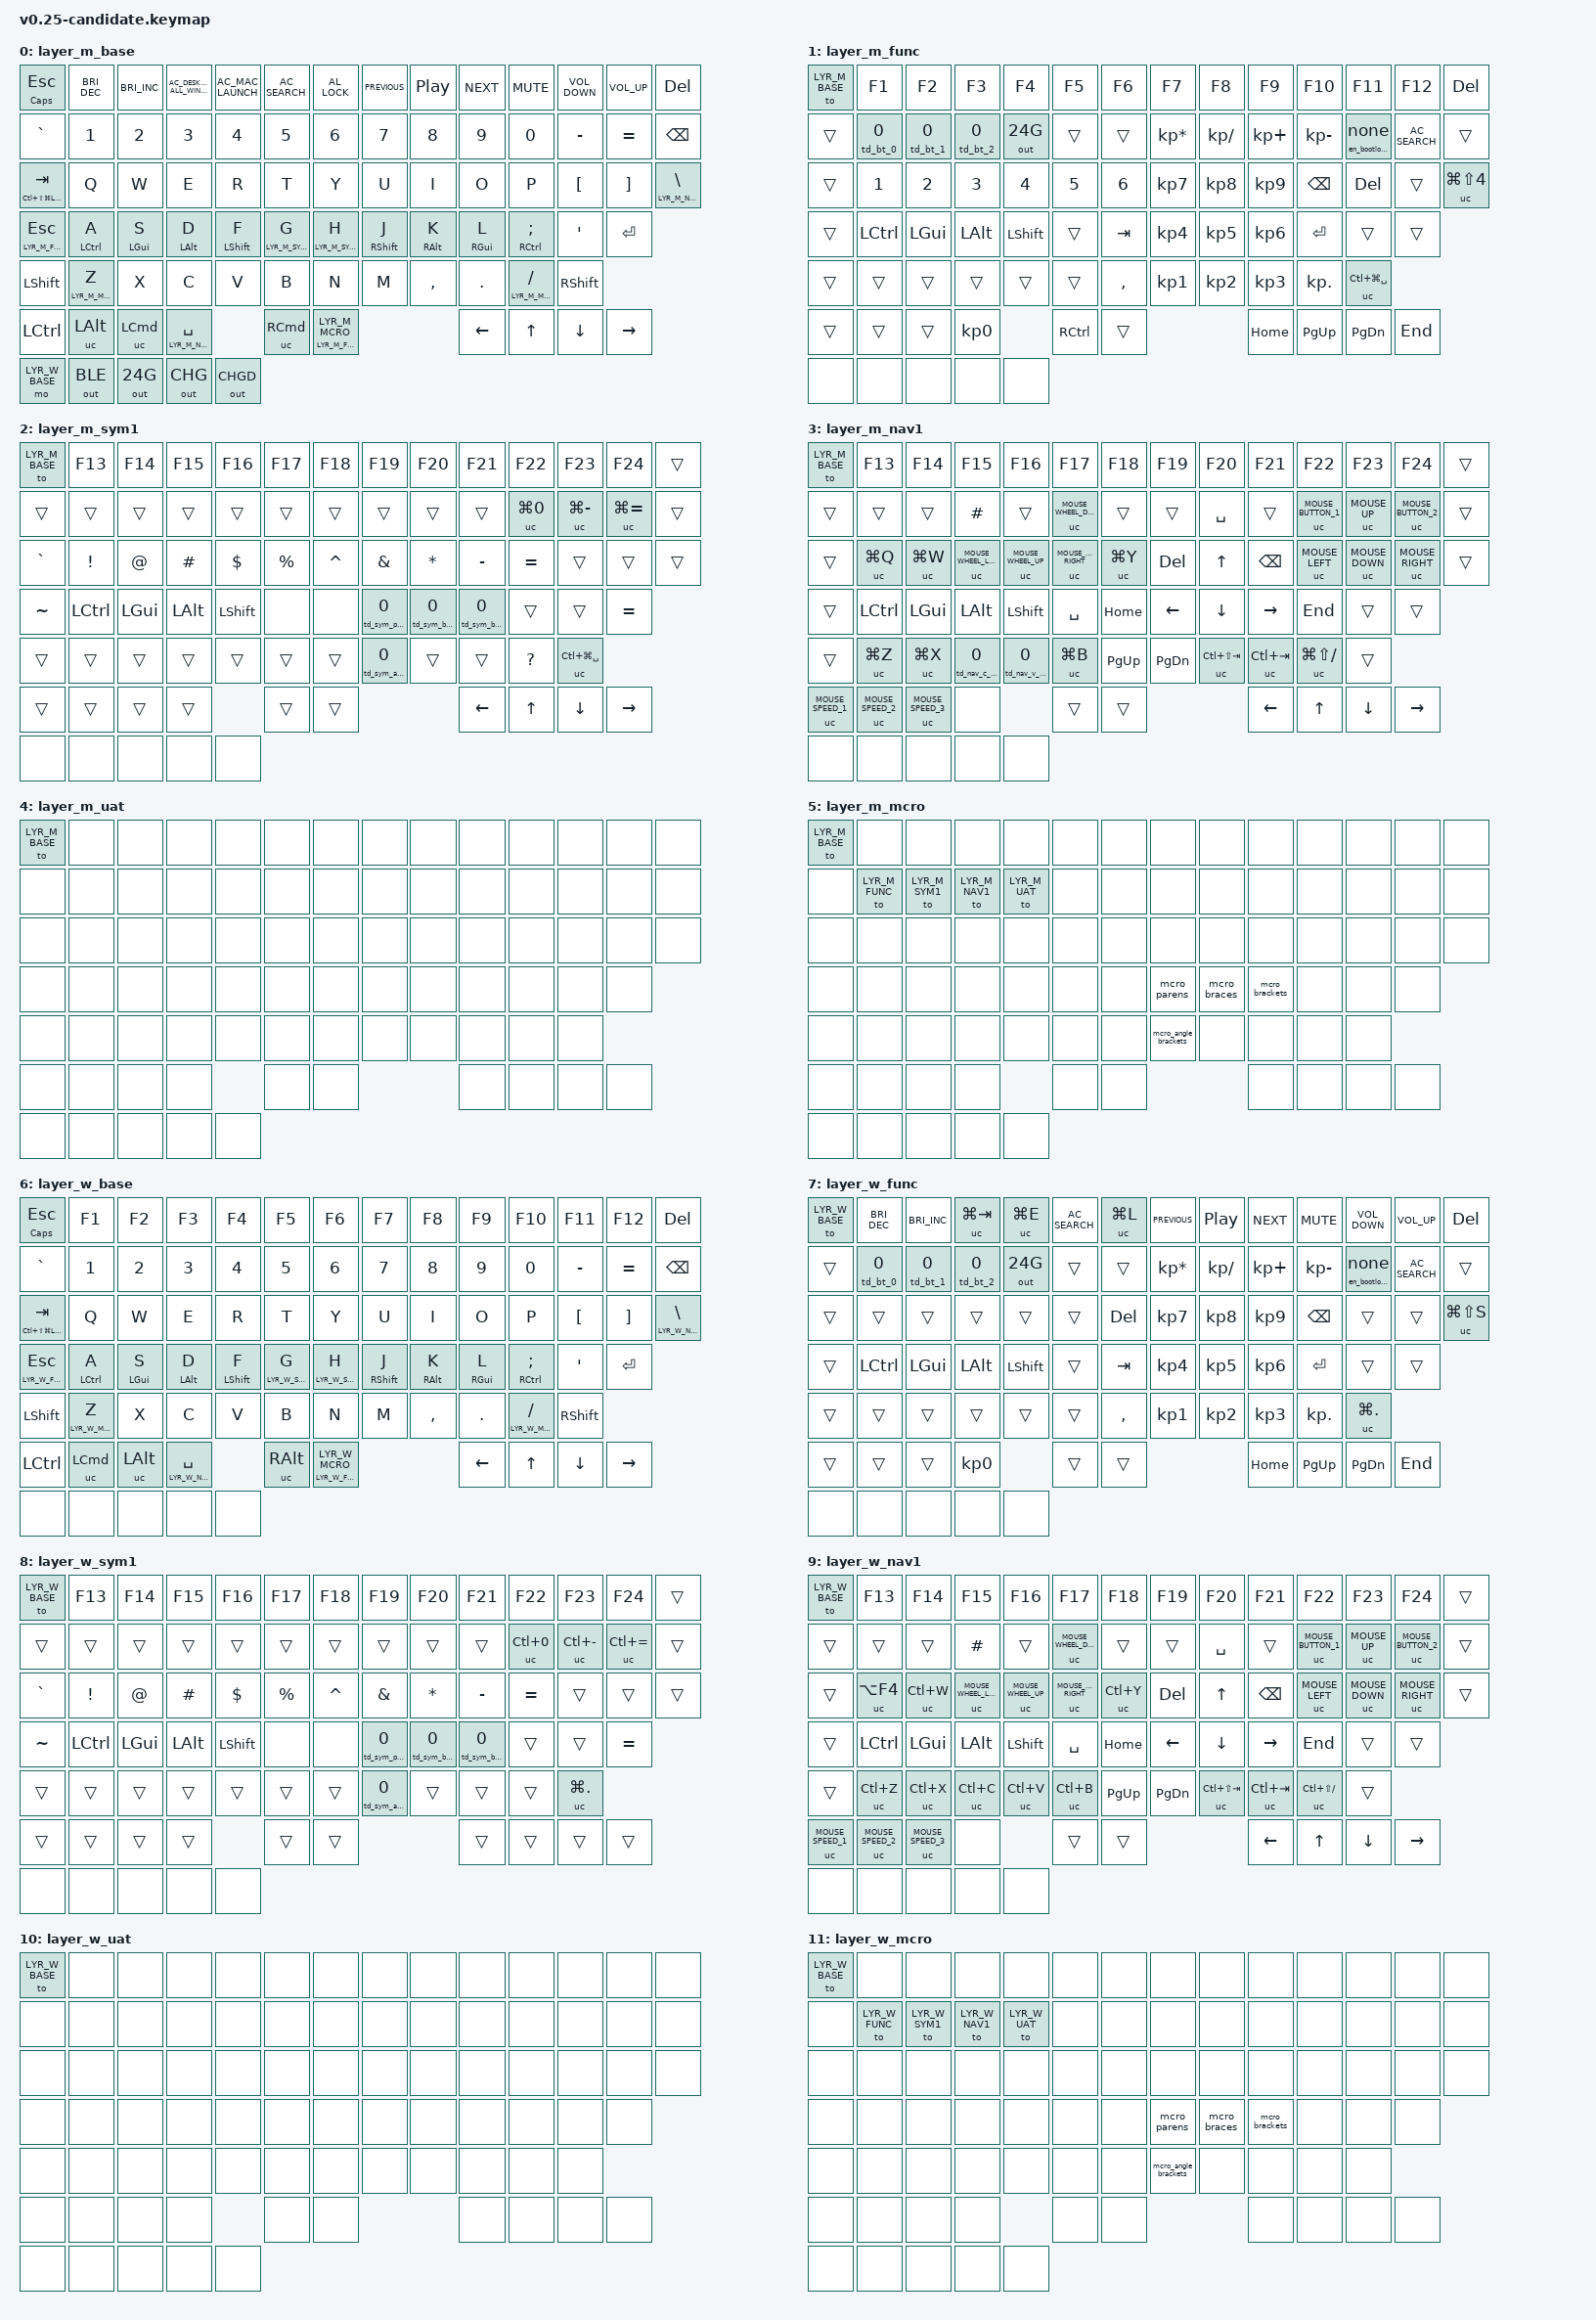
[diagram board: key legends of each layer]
/*
 * Keychron B1 Pro v0.25 candidate.
 * SYMBOL Layers (2 & 8): Reduced bracket tap-dance to 2 taps max (tap: open, double-tap: close) with 350ms threshold.
 *   Restored direct &kp MINUS and &kp EQUAL (Shift + F yields _ and +; rapid double-tap yields -- and ==).
 * MACRO Layers (5 & 11): Momentary layer access via hold Z or hold / (FSLH). Assigned auto-closing bracket macros (open + close + left arrow) to J, K, L, M.
 */

#include <behaviors.dtsi>
#include <dt-bindings/zmk/keys.h>
#include <dt-bindings/zmk/bt.h>
#include <dt-bindings/zmk/outputs.h>

#define LYR_M_BASE        0
#define LYR_M_FUNC        1
#define LYR_M_SYM1        2
#define LYR_M_NAV1        3
#define LYR_M_UAT         4
#define LYR_M_MCRO        5
#define LYR_W_BASE        6
#define LYR_W_FUNC        7
#define LYR_W_SYM1        8
#define LYR_W_NAV1        9
#define LYR_W_UAT         10
#define LYR_W_MCRO        11

#define MOUSE_UP          0x00CD
#define MOUSE_DOWN        0x00CE
#define MOUSE_LEFT        0x00CF
#define MOUSE_RIGHT       0x00D0
#define MOUSE_BUTTON_1    0x00D1
#define MOUSE_BUTTON_2    0x00D2
#define MOUSE_WHEEL_UP    0x00D9
#define MOUSE_WHEEL_DOWN  0x00DA
#define MOUSE_WHEEL_LEFT  0x00DB
#define MOUSE_WHEEL_RIGHT 0x00DC
#define MOUSE_SPEED_1     0x00DD
#define MOUSE_SPEED_2     0x00DE
#define MOUSE_SPEED_3     0x00DF

/ {
    ZMK_MACRO(en_bootloader, bindings = <&bootloader>;)
    ZMK_MACRO(mcro_parens, bindings = <&kp LPAR &kp RPAR &kp LEFT>;)
    ZMK_MACRO(mcro_braces, bindings = <&kp LBRC &kp RBRC &kp LEFT>;)
    ZMK_MACRO(mcro_brackets, bindings = <&kp LBKT &kp RBKT &kp LEFT>;)
    ZMK_MACRO(mcro_angle_brackets, bindings = <&kp LT &kp GT &kp LEFT>;)

    long_press_bootloader: long_press_bootloader {
        compatible = "zmk,behavior-hold-tap";
        label = "LP_BOOTLOADER";
        #binding-cells = <2>;
        flavor = "tap-preferred";
        tapping-term-ms = <3000>;  // delay amount in ms
        bindings = <&en_bootloader>, <&none>;
    };

    esc_caps: escape_caps_lock {
        compatible = "zmk,behavior-hold-tap";
        label = "ESC_CAPS_LOCK";
        #binding-cells = <2>;
        flavor = "tap-preferred";
        tapping-term-ms = <600>;
        // Use an ordinary press/release for the hold. &kt keeps CLCK down
        // across physical releases, which requires a second hold to finish.
        bindings = <&kp>, <&kp>;
    };

    fn_layer_access: fn_layer_access {
        compatible = "zmk,behavior-hold-tap";
        label = "FN_LAYER_ACCESS";
        #binding-cells = <2>;
        flavor = "tap-preferred";
        tapping-term-ms = <200>;
        bindings = <&mo>, <&sl>;
    };

    td_bt_0: td_bt_0 {
        compatible = "zmk,behavior-tap-dance";
        label = "TD_BT_0";
        #binding-cells = <1>;
        tapping-term-ms = <350>;
        bindings = <&bt BT_SEL 0>, <&bt BT_PAIR 0>;
    };

    td_bt_1: td_bt_1 {
        compatible = "zmk,behavior-tap-dance";
        label = "TD_BT_1";
        #binding-cells = <1>;
        tapping-term-ms = <350>;
        bindings = <&bt BT_SEL 1>, <&bt BT_PAIR 1>;
    };

    td_bt_2: td_bt_2 {
        compatible = "zmk,behavior-tap-dance";
        label = "TD_BT_2";
        #binding-cells = <1>;
        tapping-term-ms = <350>;
        bindings = <&bt BT_SEL 2>, <&bt BT_PAIR 2>;
    };

    td_sym_parens: td_sym_parens {
        compatible = "zmk,behavior-tap-dance";
        label = "TD_SYM_PARENS";
        #binding-cells = <1>;
        tapping-term-ms = <350>;
        bindings = <&kp LPAR>, <&kp RPAR>;
    };

    td_sym_braces: td_sym_braces {
        compatible = "zmk,behavior-tap-dance";
        label = "TD_SYM_BRACES";
        #binding-cells = <1>;
        tapping-term-ms = <350>;
        bindings = <&kp LBRC>, <&kp RBRC>;
    };

    td_sym_brackets: td_sym_brackets {
        compatible = "zmk,behavior-tap-dance";
        label = "TD_SYM_BRACKETS";
        #binding-cells = <1>;
        tapping-term-ms = <350>;
        bindings = <&kp LBKT>, <&kp RBKT>;
    };

    td_sym_angle_brackets: td_sym_angle_brackets {
        compatible = "zmk,behavior-tap-dance";
        label = "TD_SYM_ANGLE_BRACKETS";
        #binding-cells = <1>;
        tapping-term-ms = <350>;
        bindings = <&kp LT>, <&kp GT>;
    };

    td_nav_c_mac: td_nav_c_mac {
        compatible = "zmk,behavior-tap-dance";
        label = "TD_NAV_C_MAC";
        #binding-cells = <1>;
        tapping-term-ms = <200>;
        bindings = <&uc LG(C)>, <&uc LG(LS(C))>, <&uc LC(LS(C))>;
    };

    td_nav_v_mac: td_nav_v_mac {
        compatible = "zmk,behavior-tap-dance";
        label = "TD_NAV_V_MAC";
        #binding-cells = <1>;
        tapping-term-ms = <200>;
        bindings = <&uc LG(V)>, <&uc LC(V)>, <&uc LC(LS(V))>;
    };

    lhm: left_homerow_mods {
        compatible = "zmk,behavior-hold-tap";
        label = "LEFT_HOMEROW_MODS";
        #binding-cells = <2>;
        flavor = "tap-preferred";
        tapping-term-ms = <200>;
        quick-tap-ms = <175>;
        require-prior-idle-ms = <150>;
        hold-trigger-on-release;
        hold-trigger-key-positions = <
            7 8 9 10 11 12
            20 21 22 23 24 25 26
            34 35 36 37 38 39 40
            47 48 49 50 51 52 53
            60 61 62 63 64 65
            70 71 72 73 74 75
        >;
        bindings = <&kp>, <&kp>;
    };

    rhm: right_homerow_mods {
        compatible = "zmk,behavior-hold-tap";
        label = "RIGHT_HOMEROW_MODS";
        #binding-cells = <2>;
        flavor = "tap-preferred";
        tapping-term-ms = <200>;
        quick-tap-ms = <175>;
        require-prior-idle-ms = <150>;
        hold-trigger-on-release;
        hold-trigger-key-positions = <
            0 1 2 3 4 5 6
            13 14 15 16 17 18 19
            27 28 29 30 31 32 33
            41 42 43 44 45 46
            54 55 56 57 58 59
            66 67 68 69
        >;
        bindings = <&kp>, <&kp>;
    };


    uc: user_custom {
        compatible = "zmk,behavior-key-press";
        label = "USER_CUSTOM";
        #binding-cells = <1>;
    };

    keymap {

    /*
                              ..'
                      ,xNMM.
                    .OMMMMo
                    lMM"
          .;loddo:.  .olloddol;.
        cKMMMMMMMMMMNWMMMMMMMMMM0:
      .KMMMMMMMMMMMMMMMMMMMMMMMWd.
      XMMMMMMMMMMMMMMMMMMMMMMMX.
      ;MMMMMMMMMMMMMMMMMMMMMMMM:
      :MMMMMMMMMMMMMMMMMMMMMMMM:
      .MMMMMMMMMMMMMMMMMMMMMMMMX.
      kMMMMMMMMMMMMMMMMMMMMMMMMWd.
      'XMMMMMMMMMMMMMMMMMMMMMMMMMMk
        'XMMMMMMMMMMMMMMMMMMMMMMMMK.
          kMMMMMMMMMMMMMMMMMMMMMMd
          ;KMMMMMMMWXXWMMMMMMMk.
            "cooc*"    "*coo'"
                                      */
    compatible = "zmk,keymap";
    /* LAYER 0: LYR_M_BASE
    ┏━━━━━━━━━━━┳━━━━━━━━━┳━━━━━━━━━┳━━━━━━━━━┳━━━━━━━━━┳━━━━━━━━━┳━━━━━━━━━┳━━━━━━━━━┳━━━━━━━━━┳━━━━━━━━━┳━━━━━━━━━┳━━━━━━━━━┳━━━━━━━━━┳━━━━━━━━┓
    ┃           ┃         ┃         ┃ MISSION ┃   MAC   ┃  SEARCH ┃ CTRL+ALT┃ PREVIOUS┃ PLAY/   ┃   NEXT  ┃   Vol   ┃         ┃         ┃        ┃
    ┃TAP: ESC   ┃ Bright- ┃ Bright+ ┃ CONTROL ┃ LAUNCH  ┃         ┃    + M  ┃  TRACK  ┃  PAUSE  ┃  TRACK  ┃   Mute  ┃   Vol-  ┃  Vol+   ┃   DEL  ┃
    ┃HOLD: CAPS ┃         ┃         ┃         ┃         ┃         ┃         ┃         ┃         ┃         ┃         ┃         ┃         ┃        ┃
    ┣━━━━━━━┳━━━┻━━━━━┳━━━┻━━━━━┳━━━┻━━━━━┳━━━┻━━━━━┳━━━┻━━━━━┳━━━┻━━━━━┳━━━┻━━━━━┳━━━┻━━━━━┳━━━┻━━━━━┳━━━┻━━━━━┳━━━┻━━━━━┳━━━┻━━━━━┳━━━┻━━━━━━━━┫
    ┃   ~   ┃    !    ┃    @    ┃    #    ┃    $    ┃    %    ┃    ^    ┃    *    ┃    -    ┃    (    ┃    )    ┃    _    ┃    +    ┃            ┃
    ┃   `   ┃    1    ┃    2    ┃    3    ┃    4    ┃    5    ┃    6    ┃    7    ┃    8    ┃    9    ┃    0    ┃    -    ┃    =    ┃    BKSP    ┃
    ┃       ┃         ┃         ┃         ┃         ┃         ┃         ┃         ┃         ┃         ┃         ┃         ┃         ┃            ┃
    ┣━━━━━━━┻━━┳━━━━━━┻━━┳━━━━━━┻━━┳━━━━━━┻━━┳━━━━━━┻━━┳━━━━━━┻━━┳━━━━━━┻━━┳━━━━━━┻━━┳━━━━━━┻━━┳━━━━━━┻━━┳━━━━━━┻━━┳━━━━━━┻━━┳━━━━━━┻━━┳━━━━━━━━━┫
    ┃TAP: TAB  ┃         ┃         ┃         ┃         ┃         ┃         ┃         ┃         ┃         ┃         ┃    {    ┃    }    ┃    |    ┃
    ┃HOLD: HYPR┃    Q    ┃    W    ┃    E    ┃    R    ┃    T    ┃    Y    ┃    U    ┃    I    ┃    O    ┃    P    ┃    [    ┃    ]    ┃    \    ┃
    ┃          ┃         ┃         ┃         ┃         ┃         ┃         ┃         ┃         ┃         ┃         ┃         ┃         ┃         ┃
    ┣━━━━━━━━━━┻┳━━━━━━━━┻┳━━━━━━━━┻┳━━━━━━━━┻┳━━━━━━━━┻┳━━━━━━━━┻┳━━━━━━━━┻┳━━━━━━━━┻┳━━━━━━━━┻┳━━━━━━━━┻┳━━━━━━━━┻┳━━━━━━━━┻┳━━━━━━━━┻━━━━━━━━━┫
    ┃TAP=ESC    ┃ TAP=A   ┃ TAP=S   ┃ TAP=D   ┃ TAP=F   ┃ TAP=G   ┃ TAP=H   ┃ TAP=J   ┃ TAP=K   ┃ TAP=L   ┃ TAP=;/: ┃    "    ┃                  ┃
    ┃HOLD:MO(1) ┃ HLD=    ┃ HLD=    ┃ HLD=    ┃ HLD=    ┃ HLD=    ┃ HLD=    ┃ HLD=    ┃ HLD=    ┃ HLD=    ┃ HLD=    ┃    '    ┃      RETURN      ┃
    ┃           ┃  L_CTRL ┃  L_GUI  ┃  L_ALT  ┃ L_SHIFT ┃   MO(2) ┃   MO(2) ┃ R_SHIFT ┃  R_ALT  ┃  R_GUI  ┃  R_CTRL ┃         ┃                  ┃
    ┣━━━━━━━━━━━┻━━┳━━━━━━┻━━┳━━━━━━┻━━┳━━━━━━┻━━┳━━━━━━┻━━┳━━━━━━┻━━┳━━━━━━┻━━┳━━━━━━┻━━┳━━━━━━┻━━┳━━━━━━┻━━┳━━━━━━┻━━┳━━━━━━┻━━━━━━━━━━━━━━━━━━┫
    ┃              ┃         ┃         ┃         ┃         ┃         ┃         ┃         ┃    <    ┃    >    ┃    ?    ┃                         ┃
    ┃   L_SHIFT    ┃    Z    ┃    X    ┃    C    ┃    V    ┃    B    ┃   N     ┃    M    ┃    ,    ┃    .    ┃    /    ┃        R_SHIFT          ┃
    ┃              ┃         ┃         ┃         ┃         ┃         ┃         ┃         ┃         ┃         ┃         ┃                         ┃
    ┣━━━━━━━━━━━┳━━┻━━━━━━━┳━┻━━━━━━━━━╋━━━━━━━━━┻━━━━━━━━━┻━━━━━━━━━┻━━━━━━━━━┻━━━━━━━━━╋━━━━━━━━━┻━━━━┳━━━━┻━━━━━┳━┳━┻━━━━━━┳━━━━━━━━━┳━━━━━━━━┫
    ┃           ┃          ┃           ┃                                                 ┃              ┃TAP:OSL(5)┃ ┃        ┃    ↑    ┃        ┃
    ┃  L_CTRL   ┃  L_ALT   ┃   L_CMD   ┃             * &lt LYR_M_NAV1 SPACE *            ┃    R_CMD     ┃HOLD:MO(1)┃ ┃    ←   ┣━━━━━━━━━┫   →    ┃
    ┃           ┃          ┃           ┃                                                 ┃              ┃          ┃ ┃        ┃    ↓    ┃        ┃
    ┗━━━━━━━━━━━┻━━━━━━━━━━┻━━━━━━━━━━━┻━━━━━━━━━━━━━━━━━━━━━━━━━━━━━━━━━━━━━━━━━━━━━━━━━┻━━━━━━━━━━━━━━┻━━━━━━━━━━┛ ┗━━━━━━━━┻━━━━━━━━━┻━━━━━━━━┛
    */

    layer_m_base {
      bindings = <
        //ESC                     //f1                   //f2                  //f3                               //f4                 //f5              //f6              //f7            //f8              //f9        //f10            //f11              //f12            //DEL
        &esc_caps CLCK ESC        &kp C_BRIGHTNESS_DEC   &kp C_BRIGHTNESS_INC  &kp C_AC_DESKTOP_SHOW_ALL_WINDOWS  &kp C_AC_MAC_LAUNCH  &kp C_AC_SEARCH   &kp C_AL_LOCK     &kp C_PREVIOUS  &kp C_PLAY_PAUSE  &kp C_NEXT  &kp C_MUTE       &kp C_VOLUME_DOWN  &kp C_VOLUME_UP  &kp DEL
        &kp GRAVE                 &kp N1                 &kp N2                &kp N3                             &kp N4               &kp N5            &kp N6            &kp N7          &kp N8            &kp N9      &kp N0           &kp MINUS          &kp EQUAL        &kp BSPC
        &mt LC(LS(LG(LALT))) TAB  &kp Q                  &kp W                 &kp E                              &kp R                &kp T             &kp Y             &kp U           &kp I             &kp O       &kp P            &kp LBKT           &kp RBKT         &lt LYR_M_NAV1 BSLH
        &lt LYR_M_FUNC ESC        &lhm LCTRL A           &lhm LGUI S           &lhm LALT D                        &lhm LSHFT F         &lt LYR_M_SYM1 G  &lt LYR_M_SYM1 H  &rhm RSHFT J    &rhm RALT K       &rhm RGUI L &rhm RCTRL SEMI  &kp SQT            &kp RET
        &kp LSHFT                 &lt LYR_M_MCRO Z       &kp X                 &kp C                              &kp V                &kp B             &kp N             &kp M           &kp COMMA         &kp DOT     &lt LYR_M_MCRO FSLH  &kp RSHFT
        &kp LCTRL                 &uc LALT               &uc LCMD              &lt LYR_M_NAV1 SPACE                                    &uc RCMD          &fn_layer_access LYR_M_FUNC LYR_M_MCRO              &kp LEFT    &kp UP           &kp DOWN           &kp RIGHT
        &mo LYR_W_BASE            &out OUT_BLE           &out OUT_24G          &out OUT_CHG                       &out OUT_CHGD
      >;
    };

    /* LAYER 1: LYR_M_FUNC
    ┏━━━━━━━━━━━┳━━━━━━━━━┳━━━━━━━━━┳━━━━━━━━━┳━━━━━━━━━┳━━━━━━━━━┳━━━━━━━━━┳━━━━━━━━━┳━━━━━━━━━┳━━━━━━━━━┳━━━━━━━━━┳━━━━━━━━━┳━━━━━━━━━┳━━━━━━━━┓
    ┃           ┃         ┃         ┃         ┃         ┃         ┃         ┃         ┃         ┃         ┃         ┃         ┃         ┃        ┃
    ┃TO(LYR_M_  ┃   F1    ┃   F2    ┃   F3    ┃   F4    ┃   F5    ┃   F6    ┃    F7   ┃    F8   ┃    F9   ┃   F10   ┃   F11   ┃   F12   ┃  DEL   ┃
    ┃   BASE)   ┃         ┃         ┃         ┃         ┃         ┃         ┃         ┃         ┃         ┃         ┃         ┃         ┃        ┃
    ┣━━━━━━━┳━━━┻━━━━━┳━━━┻━━━━━┳━━━┻━━━━━┳━━━┻━━━━━┳━━━┻━━━━━┳━━━┻━━━━━┳━━━┻━━━━━┳━━━┻━━━━━┳━━━┻━━━━━┳━━━┻━━━━━┳━━━┻━━━━━┳━━━┻━━━━━┳━━━┻━━━━━━━━┫
    ┃       ┃TAP:BT1  ┃TAP:BT2  ┃TAP:BT3  ┃  2.4G   ┃         ┃         ┃ NUMPAD  ┃ NUMPAD  ┃ NUMPAD  ┃ NUMPAD  ┃         ┃         ┃            ┃
    ┃   ▼   ┃DBL:PAIR1┃DBL:PAIR2┃DBL:PAIR3┃  PAIR   ┃    ▼    ┃    ▼    ┃    ×    ┃    ÷    ┃    +    ┃    −    ┃   Boot  ┃  Search ┃     ▼      ┃
    ┃       ┃         ┃         ┃         ┃         ┃         ┃         ┃         ┃         ┃         ┃         ┃         ┃         ┃            ┃
    ┣━━━━━━━┻━━┳━━━━━━┻━━┳━━━━━━┻━━┳━━━━━━┻━━┳━━━━━━┻━━┳━━━━━━┻━━┳━━━━━━┻━━┳━━━━━━┻━━┳━━━━━━┻━━┳━━━━━━┻━━┳━━━━━━┻━━┳━━━━━━┻━━┳━━━━━━┻━━┳━━━━━━━━━┫
    ┃          ┃    !    ┃    @    ┃    #    ┃    $    ┃    %    ┃    ^    ┃ NUMPAD  ┃ NUMPAD  ┃ NUMPAD  ┃         ┃         ┃         ┃ Screen  ┃
    ┃     ▼    ┃    1    ┃    2    ┃    3    ┃    4    ┃    5    ┃    6    ┃    7    ┃    8    ┃    9    ┃BACKSPACE┃  DELETE ┃    ▼    ┃ Cap-Mac ┃
    ┃          ┃         ┃         ┃         ┃         ┃         ┃         ┃         ┃         ┃         ┃         ┃         ┃         ┃         ┃
    ┣━━━━━━━━━━┻┳━━━━━━━━┻┳━━━━━━━━┻┳━━━━━━━━┻┳━━━━━━━━┻┳━━━━━━━━┻┳━━━━━━━━┻┳━━━━━━━━┻┳━━━━━━━━┻┳━━━━━━━━┻┳━━━━━━━━┻┳━━━━━━━━┻┳━━━━━━━━┻━━━━━━━━━┫
    ┃           ┃         ┃         ┃         ┃         ┃         ┃ NUMPAD  ┃ NUMPAD  ┃ NUMPAD  ┃ NUMPAD  ┃         ┃         ┃                  ┃
    ┃   __▼__   ┃  L_CTRL ┃  L_GUI  ┃  L_ALT  ┃ L_SHIFT ┃     ▼   ┃   TAB   ┃    4    ┃    5    ┃    6    ┃  ENTER  ┃     ▼   ┃         ▼        ┃
    ┃           ┃         ┃         ┃         ┃         ┃         ┃         ┃         ┃         ┃         ┃         ┃         ┃                  ┃
    ┣━━━━━━━━━━━┻━━┳━━━━━━┻━━┳━━━━━━┻━━┳━━━━━━┻━━┳━━━━━━┻━━┳━━━━━━┻━━┳━━━━━━┻━━┳━━━━━━┻━━┳━━━━━━┻━━┳━━━━━━┻━━┳━━━━━━┻━━┳━━━━━━┻━━━━━━━━━━━━━━━━━━┫
    ┃              ┃         ┃         ┃         ┃         ┃         ┃         ┃ NUMPAD  ┃ NUMPAD  ┃ NUMPAD  ┃ NUMPAD  ┃                         ┃
    ┃       ▼      ┃     ▼   ┃     ▼   ┃     ▼   ┃    ▼    ┃    ▼    ┃    ,    ┃    1    ┃    2    ┃    3    ┃    .    ┃        Emoji-m          ┃
    ┃              ┃         ┃         ┃         ┃         ┃         ┃         ┃         ┃         ┃         ┃         ┃                         ┃
    ┣━━━━━━━━━━━┳━━┻━━━━━━━┳━┻━━━━━━━━━╋━━━━━━━━━┻━━━━━━━━━┻━━━━━━━━━┻━━━━━━━━━┻━━━━━━━━━╋━━━━━━━━━┻━━━━┳━━━━┻━━━━━┳━┳━┻━━━━━━┳━━━━━━━━━┳━━━━━━━━┫
    ┃           ┃          ┃           ┃                     NUMPAD                      ┃              ┃          ┃ ┃        ┃  PgUp   ┃        ┃
    ┃     ▼     ┃     ▼    ┃     ▼     ┃                        0                        ┃    R_CTRL    ┃     ▼    ┃ ┃  Home  ┣━━━━━━━━━┫   End  ┃
    ┃           ┃          ┃           ┃                                                 ┃              ┃          ┃ ┃        ┃  PgDn   ┃        ┃
    ┗━━━━━━━━━━━┻━━━━━━━━━━┻━━━━━━━━━━━┻━━━━━━━━━━━━━━━━━━━━━━━━━━━━━━━━━━━━━━━━━━━━━━━━━┻━━━━━━━━━━━━━━┻━━━━━━━━━━┛ ┗━━━━━━━━┻━━━━━━━━━┻━━━━━━━━┛
    */
    layer_m_func {
      bindings = <
        //ESC           //F1        //F2        //F3        //f4          //f5    //f6       //f7             //f8           //f9         //f10         //f11                       //f12             //DEL
        &to LYR_M_BASE  &kp F1      &kp F2      &kp F3      &kp F4        &kp F5  &kp F6     &kp F7           &kp F8         &kp F9       &kp F10       &kp F11                     &kp F12           &kp DEL
        &trans          &td_bt_0 0  &td_bt_1 0  &td_bt_2 0  &out OUT_24G  &trans  &trans     &kp KP_MULTIPLY  &kp KP_DIVIDE  &kp KP_PLUS  &kp KP_MINUS  &long_press_bootloader 0 0  &kp C_AC_SEARCH   &trans
        &trans          &kp N1      &kp N2      &kp N3      &kp N4        &kp N5  &kp N6     &kp KP_N7        &kp KP_N8      &kp KP_N9    &kp BSPC      &kp DEL                      &trans            &uc LG(LS(N4))
        &trans          &kp LCTRL   &kp LGUI    &kp LALT    &kp LSHFT     &trans  &kp TAB    &kp KP_N4        &kp KP_N5      &kp KP_N6    &kp RET       &trans                                        &trans
        &trans          &trans      &trans      &trans      &trans        &trans  &kp COMMA  &kp KP_N1        &kp KP_N2      &kp KP_N3    &kp KP_DOT    &uc LC(LG(SPACE))
        &trans          &trans      &trans      &kp KP_N0   &kp RCTRL     &trans  &kp HOME   &kp PG_UP        &kp PG_DN      &kp END
        &none           &none       &none       &none       &none
      >;
    };

    /* LAYER 2: LYR_M_SYM1
    ┏━━━━━━━━━━━┳━━━━━━━━━┳━━━━━━━━━┳━━━━━━━━━┳━━━━━━━━━┳━━━━━━━━━┳━━━━━━━━━┳━━━━━━━━━┳━━━━━━━━━┳━━━━━━━━━┳━━━━━━━━━┳━━━━━━━━━┳━━━━━━━━━┳━━━━━━━━┓
    ┃           ┃         ┃         ┃         ┃         ┃         ┃         ┃         ┃         ┃         ┃         ┃         ┃         ┃        ┃
    ┃TO(LYR_M_  ┃   F13   ┃   F14   ┃   F15   ┃   F16   ┃   F17   ┃   F18   ┃   F19   ┃   F20   ┃   F21   ┃   F22   ┃   F23   ┃   F24   ┃   ▼    ┃
    ┃   BASE)   ┃         ┃         ┃         ┃         ┃         ┃         ┃         ┃         ┃         ┃         ┃         ┃         ┃        ┃
    ┣━━━━━━━┳━━━┻━━━━━┳━━━┻━━━━━┳━━━┻━━━━━┳━━━┻━━━━━┳━━━┻━━━━━┳━━━┻━━━━━┳━━━┻━━━━━┳━━━┻━━━━━┳━━━┻━━━━━┳━━━┻━━━━━┳━━━┻━━━━━┳━━━┻━━━━━┳━━━┻━━━━━━━━┫
    ┃       ┃         ┃         ┃         ┃         ┃         ┃         ┃         ┃         ┃         ┃         ┃         ┃         ┃            ┃
    ┃   ▼   ┃    ▼    ┃    ▼    ┃    ▼    ┃    ▼    ┃    ▼    ┃    ▼    ┃    ▼    ┃    ▼    ┃    ▼    ┃ LG(N0)  ┃LG(MINUS)┃LG(EQUAL)┃     ▼      ┃
    ┃       ┃         ┃         ┃         ┃         ┃         ┃         ┃         ┃         ┃         ┃         ┃         ┃         ┃            ┃
    ┣━━━━━━━┻━━┳━━━━━━┻━━┳━━━━━━┻━━┳━━━━━━┻━━┳━━━━━━┻━━┳━━━━━━┻━━┳━━━━━━┻━━┳━━━━━━┻━━┳━━━━━━┻━━┳━━━━━━┻━━┳━━━━━━┻━━┳━━━━━━┻━━┳━━━━━━┻━━┳━━━━━━━━━┫
    ┃          ┃         ┃         ┃         ┃         ┃         ┃         ┃         ┃         ┃         ┃         ┃         ┃         ┃S(KC_    ┃
    ┃    [`]   ┃   [!]   ┃   [@]   ┃   [#]   ┃   [$]   ┃   [%]   ┃   [^]   ┃   [&]   ┃   [*]   ┃   [-]   ┃   [=]   ┃    ▼    ┃    ▼    ┃  BSLS)  ┃
    ┃          ┃         ┃         ┃         ┃         ┃         ┃         ┃         ┃         ┃         ┃         ┃         ┃         ┃         ┃
    ┣━━━━━━━━━━┻┳━━━━━━━━┻┳━━━━━━━━┻┳━━━━━━━━┻┳━━━━━━━━┻┳━━━━━━━━┻┳━━━━━━━━┻┳━━━━━━━━┻┳━━━━━━━━┻┳━━━━━━━━┻┳━━━━━━━━┻┳━━━━━━━━┻┳━━━━━━━━┻━━━━━━━━━┫
    ┃           ┃         ┃         ┃         ┃         ┃    *    ┃   *     ┃ 1TAP: ( ┃ 1TAP: { ┃ 1TAP: [ ┃         ┃         ┃                  ┃
    ┃    [~]    ┃  L_CTRL ┃  L_GUI  ┃  L_ALT  ┃ L_SHIFT ┃  SYMBOL ┃ SYMBOL  ┃ 2TAP: ) ┃ 2TAP: } ┃ 2TAP: ] ┃    ▼    ┃    ▼    ┃       [=]        ┃
    ┃           ┃         ┃         ┃         ┃         ┃    *    ┃   *     ┃         ┃         ┃         ┃         ┃         ┃                  ┃
    ┣━━━━━━━━━━━┻━━┳━━━━━━┻━━┳━━━━━━┻━━┳━━━━━━┻━━┳━━━━━━┻━━┳━━━━━━┻━━┳━━━━━━┻━━┳━━━━━━┻━━┳━━━━━━┻━━┳━━━━━━┻━━┳━━━━━━┻━━┳━━━━━━┻━━━━━━━━━━━━━━━━━━┫
    ┃              ┃         ┃         ┃         ┃         ┃         ┃         ┃ 1TAP: < ┃         ┃         ┃         ┃                         ┃
    ┃       ▼      ┃    ▼    ┃    ▼    ┃    ▼    ┃    ▼    ┃    ▼    ┃    ▼    ┃ 2TAP: > ┃    ▼    ┃    ▼    ┃    ▼    ┃         Emoji-w         ┃
    ┃              ┃         ┃         ┃         ┃         ┃         ┃         ┃         ┃         ┃         ┃         ┃                         ┃
    ┣━━━━━━━━━━━┳━━┻━━━━━━━┳━┻━━━━━━━━━╋━━━━━━━━━┻━━━━━━━━━┻━━━━━━━━━┻━━━━━━━━━┻━━━━━━━━━╋━━━━━━━━━┻━━━━┳━━━━┻━━━━━┳━┳━┻━━━━━━┳━━━━━━━━━┳━━━━━━━━┫
    ┃           ┃          ┃           ┃                                                 ┃              ┃          ┃ ┃        ┃    ↑    ┃        ┃
    ┃     ▼     ┃    ▼     ┃     ▼     ┃                         ▼                       ┃       ▼      ┃     ▼    ┃ ┃    ←   ┣━━━━━━━━━┫   →    ┃
    ┃           ┃          ┃           ┃                                                 ┃              ┃          ┃ ┃        ┃    ↓    ┃        ┃
    ┗━━━━━━━━━━━┻━━━━━━━━━━┻━━━━━━━━━━━┻━━━━━━━━━━━━━━━━━━━━━━━━━━━━━━━━━━━━━━━━━━━━━━━━━┻━━━━━━━━━━━━━━┻━━━━━━━━━━┛ ┗━━━━━━━━┻━━━━━━━━━┻━━━━━━━━┛
    */
    layer_m_sym1 {
      bindings = <
        //ESC           //f1       //f2      //f3      //f4       //f5       //f6       //f7              //f8              //f9              //f10           //f11          //f12          //DEL
        &to LYR_M_BASE  &kp F13    &kp F14   &kp F15   &kp F16    &kp F17    &kp F18    &kp F19           &kp F20           &kp F21           &kp F22         &kp F23        &kp F24        &trans
        &trans          &trans     &trans    &trans    &trans     &trans     &trans     &trans            &trans            &trans            &uc LG(N0)      &uc LG(MINUS)  &uc LG(EQUAL)  &trans
        &kp GRAVE       &kp EXCL   &kp AT    &kp HASH  &kp DLLR   &kp PRCNT  &kp CARET  &kp AMPS          &kp ASTERISK      &kp MINUS         &kp EQUAL       &trans         &trans         &trans
        &kp TILDE       &kp LCTRL  &kp LGUI  &kp LALT  &kp LSHFT  &none      &none      &td_sym_parens 0  &td_sym_braces 0  &td_sym_brackets 0 &trans          &trans         &kp EQUAL
        &trans          &trans     &trans    &trans    &trans     &trans     &trans     &td_sym_angle_brackets 0  &trans    &trans            &kp QMARK       &uc LC(LG(SPACE))                                //SHIFTx2
        &trans          &trans     &trans    &trans    &trans     &trans     &kp LEFT   &kp UP            &kp DOWN          &kp RIGHT
        &none           &none      &none     &none     &none
      >;
    };

    /* LAYER 3: LYR_M_NAV1
    ┏━━━━━━━━━━━┳━━━━━━━━━┳━━━━━━━━━┳━━━━━━━━━┳━━━━━━━━━┳━━━━━━━━━┳━━━━━━━━━┳━━━━━━━━━┳━━━━━━━━━┳━━━━━━━━━┳━━━━━━━━━┳━━━━━━━━━┳━━━━━━━━━┳━━━━━━━━┓
    ┃           ┃         ┃         ┃         ┃         ┃         ┃         ┃         ┃         ┃         ┃         ┃         ┃         ┃        ┃
    ┃   TO(0)   ┃   F13   ┃   F14   ┃   F15   ┃   F16   ┃   F17   ┃   F18   ┃   F19   ┃   F20   ┃   F21   ┃   F22   ┃   F23   ┃   F24   ┃   ▼    ┃
    ┃           ┃         ┃         ┃         ┃         ┃         ┃         ┃         ┃         ┃         ┃         ┃         ┃         ┃        ┃
    ┣━━━━━━━┳━━━┻━━━━━┳━━━┻━━━━━┳━━━┻━━━━━┳━━━┻━━━━━┳━━━┻━━━━━┳━━━┻━━━━━┳━━━┻━━━━━┳━━━┻━━━━━┳━━━┻━━━━━┳━━━┻━━━━━┳━━━┻━━━━━┳━━━┻━━━━━┳━━━┻━━━━━━━━┫
    ┃       ┃         ┃         ┃         ┃         ┃         ┃         ┃         ┃         ┃         ┃         ┃         ┃         ┃            ┃
    ┃   ▼   ┃    ▼    ┃    ▼    ┃    #    ┃    ▼    ┃   MW ↓  ┃    ▼    ┃    ▼    ┃  SPACE  ┃    ▼    ┃  MBtn1  ┃ Mouse ↑ ┃  MBtn2  ┃     ▼      ┃
    ┃       ┃         ┃         ┃         ┃         ┃         ┃         ┃         ┃         ┃         ┃         ┃         ┃         ┃            ┃
    ┣━━━━━━━┻━━┳━━━━━━┻━━┳━━━━━━┻━━┳━━━━━━┻━━┳━━━━━━┻━━┳━━━━━━┻━━┳━━━━━━┻━━┳━━━━━━┻━━┳━━━━━━┻━━┳━━━━━━┻━━┳━━━━━━┻━━┳━━━━━━┻━━┳━━━━━━┻━━┳━━━━━━━━━┫
    ┃          ┃         ┃         ┃         ┃         ┃         ┃         ┃         ┃         ┃         ┃         ┃         ┃         ┃         ┃
    ┃     ▼    ┃  LG(Q)  ┃  LG(W)  ┃  MW ←   ┃  MW ↑   ┃  MW →   ┃  LG(Y)  ┃   Del   ┃    ↑    ┃  Bksp   ┃ Mouse ← ┃ Mouse ↓ ┃ Mouse → ┃    ▼    ┃
    ┃          ┃         ┃         ┃         ┃         ┃         ┃         ┃         ┃         ┃         ┃         ┃         ┃         ┃         ┃
    ┣━━━━━━━━━━┻┳━━━━━━━━┻┳━━━━━━━━┻┳━━━━━━━━┻┳━━━━━━━━┻┳━━━━━━━━┻┳━━━━━━━━┻┳━━━━━━━━┻┳━━━━━━━━┻┳━━━━━━━━┻┳━━━━━━━━┻┳━━━━━━━━┻┳━━━━━━━━┻━━━━━━━━━┫
    ┃           ┃         ┃         ┃         ┃         ┃         ┃         ┃         ┃         ┃         ┃         ┃         ┃                  ┃
    ┃      ▼    ┃  L_CTRL ┃  L_GUI  ┃  L_ALT  ┃ L_SHIFT ┃  SPACE  ┃   Home  ┃    ←    ┃    ↓    ┃    →    ┃   End   ┃    ▼    ┃        ▼         ┃
    ┃           ┃         ┃         ┃         ┃         ┃         ┃         ┃         ┃         ┃         ┃         ┃         ┃                  ┃
    ┣━━━━━━━━━━━┻━━┳━━━━━━┻━━┳━━━━━━┻━━┳━━━━━━┻━━┳━━━━━━┻━━┳━━━━━━┻━━┳━━━━━━┻━━┳━━━━━━┻━━┳━━━━━━┻━━┳━━━━━━┻━━┳━━━━━━┻━━┳━━━━━━┻━━━━━━━━━━━━━━━━━━┫
    ┃              ┃         ┃         ┃1T:LG(C) ┃1T:LG(V) ┃         ┃         ┃         ┃         ┃         ┃         ┃                         ┃
    ┃       ▼      ┃  LG(Z)  ┃  LG(X)  ┃2T:LGS(C)┃2T:LC(V) ┃  LG(B)  ┃  PgUp   ┃  PgDn   ┃LGS(TAB) ┃ LG(TAB) ┃ LGS(/)  ┃            ▼            ┃
    ┃              ┃         ┃         ┃3T:LCS(C)┃3T:LCS(V)┃         ┃         ┃         ┃         ┃         ┃         ┃                         ┃
    ┣━━━━━━━━━━━┳━━┻━━━━━━━┳━┻━━━━━━━━━╋━━━━━━━━━┻━━━━━━━━━┻━━━━━━━━━┻━━━━━━━━━┻━━━━━━━━━╋━━━━━━━━━┻━━━━┳━━━━┻━━━━━┳━┳━┻━━━━━━┳━━━━━━━━━┳━━━━━━━━┫
    ┃           ┃          ┃           ┃                                                 ┃              ┃          ┃ ┃        ┃    ↑    ┃        ┃
    ┃   MSPD1   ┃   MSPD2  ┃   MSPD3   ┃                    * IN USE *                   ┃       ▼      ┃     ▼    ┃ ┃    ←   ┣━━━━━━━━━┫   →    ┃
    ┃           ┃          ┃           ┃                                                 ┃              ┃          ┃ ┃        ┃    ↓    ┃        ┃
    ┗━━━━━━━━━━━┻━━━━━━━━━━┻━━━━━━━━━━━┻━━━━━━━━━━━━━━━━━━━━━━━━━━━━━━━━━━━━━━━━━━━━━━━━━┻━━━━━━━━━━━━━━┻━━━━━━━━━━┛ ┗━━━━━━━━┻━━━━━━━━━┻━━━━━━━━┛
    */
    layer_m_nav1 {
      bindings = <
        //ESC              //f1               //f2              //f3                  //f4                //f5                   //f6       //f7       //f8             //f9         //f10               //f11           //f12               //DEL
        &to LYR_M_BASE     &kp F13            &kp F14           &kp F15               &kp F16             &kp F17                &kp F18    &kp F19    &kp F20          &kp F21      &kp F22             &kp F23         &kp F24             &trans
        &trans             &trans              &trans           &kp HASH              &trans              &uc MOUSE_WHEEL_DOWN   &trans      &trans    &kp SPACE        &trans       &uc MOUSE_BUTTON_1  &uc MOUSE_UP    &uc MOUSE_BUTTON_2  &trans
        &trans             &uc LG(Q)          &uc LG(W)         &uc MOUSE_WHEEL_LEFT  &uc MOUSE_WHEEL_UP  &uc MOUSE_WHEEL_RIGHT  &uc LG(Y)  &kp DEL    &kp UP           &kp BSPC     &uc MOUSE_LEFT      &uc MOUSE_DOWN  &uc MOUSE_RIGHT     &trans
        &trans             &kp LCTRL          &kp LGUI          &kp LALT              &kp LSHFT           &kp SPACE              &kp HOME   &kp LEFT   &kp DOWN         &kp RIGHT    &kp END             &trans           &trans
        &trans             &uc LG(Z)          &uc LG(X)         &td_nav_c_mac 0       &td_nav_v_mac 0     &uc LG(B)              &kp PG_UP  &kp PG_DN  &uc LC(LS(TAB))  &uc LC(TAB)  &uc LG(LS(FSLH))    &trans
        &uc MOUSE_SPEED_1  &uc MOUSE_SPEED_2  &uc MOUSE_SPEED_3                       &none               &trans                 &trans     &kp LEFT   &kp UP           &kp DOWN     &kp RIGHT
        &none              &none              &none             &none                 &none
    >;
    };

    /* LAYER 4: LYR_M_UAT (reserved)
      * No Layer-0 entry point. Layer-1 selector position 18 may enter this
      * safe layer; position 0 is the sole exit and positions 1--81 are inert.
    ┏━━━━━━━━━━━┳━━━━━━━━━┳━━━━━━━━━┳━━━━━━━━━┳━━━━━━━━━┳━━━━━━━━━┳━━━━━━━━━┳━━━━━━━━━┳━━━━━━━━━┳━━━━━━━━━┳━━━━━━━━━┳━━━━━━━━━┳━━━━━━━━━┳━━━━━━━━┓
    ┃           ┃         ┃         ┃         ┃         ┃         ┃         ┃         ┃         ┃         ┃         ┃         ┃         ┃        ┃
    ┃   TO(0)   ┃         ┃         ┃         ┃         ┃         ┃         ┃         ┃         ┃         ┃         ┃         ┃         ┃        ┃
    ┃           ┃         ┃         ┃         ┃         ┃         ┃         ┃         ┃         ┃         ┃         ┃         ┃         ┃        ┃
    ┣━━━━━━━┳━━━┻━━━━━┳━━━┻━━━━━┳━━━┻━━━━━┳━━━┻━━━━━┳━━━┻━━━━━┳━━━┻━━━━━┳━━━┻━━━━━┳━━━┻━━━━━┳━━━┻━━━━━┳━━━┻━━━━━┳━━━┻━━━━━┳━━━┻━━━━━┳━━━┻━━━━━━━━┫
    ┃       ┃         ┃         ┃         ┃         ┃         ┃         ┃         ┃         ┃         ┃         ┃         ┃         ┃            ┃
    ┃       ┃         ┃         ┃         ┃         ┃         ┃         ┃         ┃         ┃         ┃         ┃         ┃         ┃            ┃
    ┃       ┃         ┃         ┃         ┃         ┃         ┃         ┃         ┃         ┃         ┃         ┃         ┃         ┃            ┃
    ┣━━━━━━━┻━━┳━━━━━━┻━━┳━━━━━━┻━━┳━━━━━━┻━━┳━━━━━━┻━━┳━━━━━━┻━━┳━━━━━━┻━━┳━━━━━━┻━━┳━━━━━━┻━━┳━━━━━━┻━━┳━━━━━━┻━━┳━━━━━━┻━━┳━━━━━━┻━━┳━━━━━━━━━┫
    ┃          ┃         ┃         ┃         ┃         ┃         ┃         ┃         ┃         ┃         ┃         ┃         ┃         ┃         ┃
    ┃          ┃         ┃         ┃         ┃         ┃         ┃         ┃         ┃         ┃         ┃         ┃         ┃         ┃         ┃
    ┃          ┃         ┃         ┃         ┃         ┃         ┃         ┃         ┃         ┃         ┃         ┃         ┃         ┃         ┃
    ┣━━━━━━━━━━┻┳━━━━━━━━┻┳━━━━━━━━┻┳━━━━━━━━┻┳━━━━━━━━┻┳━━━━━━━━┻┳━━━━━━━━┻┳━━━━━━━━┻┳━━━━━━━━┻┳━━━━━━━━┻┳━━━━━━━━┻┳━━━━━━━━┻┳━━━━━━━━┻━━━━━━━━━┫
    ┃           ┃         ┃         ┃         ┃         ┃         ┃         ┃         ┃         ┃         ┃         ┃         ┃                  ┃
    ┃           ┃         ┃         ┃         ┃         ┃         ┃         ┃         ┃         ┃         ┃         ┃         ┃                  ┃
    ┃           ┃         ┃         ┃         ┃         ┃         ┃         ┃         ┃         ┃         ┃         ┃         ┃                  ┃
    ┣━━━━━━━━━━━┻━━┳━━━━━━┻━━┳━━━━━━┻━━┳━━━━━━┻━━┳━━━━━━┻━━┳━━━━━━┻━━┳━━━━━━┻━━┳━━━━━━┻━━┳━━━━━━┻━━┳━━━━━━┻━━┳━━━━━━┻━━┳━━━━━━┻━━━━━━━━━━━━━━━━━━┫
    ┃              ┃         ┃         ┃         ┃         ┃         ┃         ┃         ┃         ┃         ┃         ┃                         ┃
    ┃              ┃         ┃         ┃         ┃         ┃         ┃         ┃         ┃         ┃         ┃         ┃                         ┃
    ┃              ┃         ┃         ┃         ┃         ┃         ┃         ┃         ┃         ┃         ┃         ┃                         ┃
    ┣━━━━━━━━━━━┳━━┻━━━━━━━┳━┻━━━━━━━━━╋━━━━━━━━━┻━━━━━━━━━┻━━━━━━━━━┻━━━━━━━━━┻━━━━━━━━━╋━━━━━━━━━┻━━━━┳━━━━┻━━━━━┳━┳━┻━━━━━━┳━━━━━━━━━┳━━━━━━━━┫
    ┃           ┃          ┃           ┃                                                 ┃              ┃          ┃ ┃        ┃         ┃        ┃
    ┃           ┃          ┃           ┃                                                 ┃              ┃          ┃ ┃        ┣━━━━━━━━━┫        ┃
    ┃           ┃          ┃           ┃                                                 ┃              ┃          ┃ ┃        ┃         ┃        ┃
    ┗━━━━━━━━━━━┻━━━━━━━━━━┻━━━━━━━━━━━┻━━━━━━━━━━━━━━━━━━━━━━━━━━━━━━━━━━━━━━━━━━━━━━━━━┻━━━━━━━━━━━━━━┻━━━━━━━━━━┛ ┗━━━━━━━━┻━━━━━━━━━┻━━━━━━━━┛
      */
    layer_m_uat {
      bindings = <
        //ESC           //f1    //f2    //f3    //f4    //f5    //f6    //f7    //f8    //f9    //f10   //f11   //f12   //DEL
        &to LYR_M_BASE  &none   &none   &none   &none   &none   &none   &none   &none   &none   &none   &none   &none   &none
        &none           &none   &none   &none   &none   &none   &none   &none   &none   &none   &none   &none   &none   &none
        &none           &none   &none   &none   &none   &none   &none   &none   &none   &none   &none   &none   &none   &none
        &none           &none   &none   &none   &none   &none   &none   &none   &none   &none   &none   &none   &none
        &none           &none   &none   &none   &none   &none   &none   &none   &none   &none   &none   &none
        &none           &none   &none   &none   &none   &none   &none   &none   &none   &none
        &none           &none   &none   &none   &none
      >;
    };

    /* LAYER 5: LYR_M_MCRO (developer macro / Fn selector / Hold Z or /)
      * Fn tap activates one-shot selector; Hold Z or / activates momentary bracket macros.
      * N1--N4 select Layers 1--4; J, K, L, M emit auto-closing brackets with cursor centering.
      * Esc exits to Layer 0. All other positions, including 77--81, are inert.
    ┏━━━━━━━━━━━┳━━━━━━━━━┳━━━━━━━━━┳━━━━━━━━━┳━━━━━━━━━┳━━━━━━━━━┳━━━━━━━━━┳━━━━━━━━━┳━━━━━━━━━┳━━━━━━━━━┳━━━━━━━━━┳━━━━━━━━━┳━━━━━━━━━┳━━━━━━━━┓
    ┃           ┃         ┃         ┃         ┃         ┃         ┃         ┃         ┃         ┃         ┃         ┃         ┃         ┃        ┃
    ┃TO(LYR_M_  ┃         ┃         ┃         ┃         ┃         ┃         ┃         ┃         ┃         ┃         ┃         ┃         ┃        ┃
    ┃   BASE)   ┃         ┃         ┃         ┃         ┃         ┃         ┃         ┃         ┃         ┃         ┃         ┃         ┃        ┃
    ┣━━━━━━━┳━━━┻━━━━━┳━━━┻━━━━━┳━━━┻━━━━━┳━━━┻━━━━━┳━━━┻━━━━━┳━━━┻━━━━━┳━━━┻━━━━━┳━━━┻━━━━━┳━━━┻━━━━━┳━━━┻━━━━━┳━━━┻━━━━━┳━━━┻━━━━━┳━━━┻━━━━━━━━┫
    ┃       ┃         ┃         ┃         ┃         ┃         ┃         ┃         ┃         ┃         ┃         ┃         ┃         ┃            ┃
    ┃       ┃TO(LYR_M_┃TO(LYR_M_┃TO(LYR_M_┃TO(LYR_M_┃         ┃         ┃         ┃         ┃         ┃         ┃         ┃         ┃            ┃
    ┃       ┃   FUNC) ┃   SYM1) ┃   NAV1) ┃   UAT)  ┃         ┃         ┃         ┃         ┃         ┃         ┃         ┃         ┃            ┃
    ┣━━━━━━━┻━━┳━━━━━━┻━━┳━━━━━━┻━━┳━━━━━━┻━━┳━━━━━━┻━━┳━━━━━━┻━━┳━━━━━━┻━━┳━━━━━━┻━━┳━━━━━━┻━━┳━━━━━━┻━━┳━━━━━━┻━━┳━━━━━━┻━━┳━━━━━━┻━━┳━━━━━━━━━┫
    ┃          ┃         ┃         ┃         ┃         ┃         ┃         ┃         ┃         ┃         ┃         ┃         ┃         ┃         ┃
    ┃          ┃         ┃         ┃         ┃         ┃         ┃         ┃         ┃         ┃         ┃         ┃         ┃         ┃         ┃
    ┃          ┃         ┃         ┃         ┃         ┃         ┃         ┃         ┃         ┃         ┃         ┃         ┃         ┃         ┃
    ┣━━━━━━━━━━┻┳━━━━━━━━┻┳━━━━━━━━┻┳━━━━━━━━┻┳━━━━━━━━┻┳━━━━━━━━┻┳━━━━━━━━┻┳━━━━━━━━┻┳━━━━━━━━┻┳━━━━━━━━┻┳━━━━━━━━┻┳━━━━━━━━┻┳━━━━━━━━┻━━━━━━━━━┫
    ┃           ┃         ┃         ┃         ┃         ┃         ┃         ┃         ┃         ┃         ┃         ┃         ┃                  ┃
    ┃           ┃         ┃         ┃         ┃         ┃         ┃         ┃  ( )+←  ┃  { }+←  ┃  [ ]+←  ┃         ┃         ┃                  ┃
    ┃           ┃         ┃         ┃         ┃         ┃         ┃         ┃         ┃         ┃         ┃         ┃         ┃                  ┃
    ┣━━━━━━━━━━━┻━━┳━━━━━━┻━━┳━━━━━━┻━━┳━━━━━━┻━━┳━━━━━━┻━━┳━━━━━━┻━━┳━━━━━━┻━━┳━━━━━━┻━━┳━━━━━━┻━━┳━━━━━━┻━━┳━━━━━━┻━━┳━━━━━━┻━━━━━━━━━━━━━━━━━━┫
    ┃              ┃         ┃         ┃         ┃         ┃         ┃         ┃         ┃         ┃         ┃         ┃                         ┃
    ┃              ┃         ┃         ┃         ┃         ┃         ┃         ┃  < >+←  ┃         ┃         ┃         ┃                         ┃
    ┃              ┃         ┃         ┃         ┃         ┃         ┃         ┃         ┃         ┃         ┃         ┃                         ┃
    ┣━━━━━━━━━━━┳━━┻━━━━━━━┳━┻━━━━━━━━━╋━━━━━━━━━┻━━━━━━━━━┻━━━━━━━━━┻━━━━━━━━━┻━━━━━━━━━╋━━━━━━━━━┻━━━━┳━━━━┻━━━━━┳━┳━┻━━━━━━┳━━━━━━━━━┳━━━━━━━━┫
    ┃           ┃          ┃           ┃                                                 ┃              ┃          ┃ ┃        ┃         ┃        ┃
    ┃           ┃          ┃           ┃                                                 ┃              ┃          ┃ ┃        ┣━━━━━━━━━┫        ┃
    ┃           ┃          ┃           ┃                                                 ┃              ┃          ┃ ┃        ┃         ┃        ┃
    ┗━━━━━━━━━━━┻━━━━━━━━━━┻━━━━━━━━━━━┻━━━━━━━━━━━━━━━━━━━━━━━━━━━━━━━━━━━━━━━━━━━━━━━━━┻━━━━━━━━━━━━━━┻━━━━━━━━━━┛ ┗━━━━━━━━┻━━━━━━━━━┻━━━━━━━━┛
      */
    layer_m_mcro {
      bindings = <
        // ESC (p0)     // F1--F12 / Del (p1--p13)
        &to LYR_M_BASE  &none           &none           &none           &none           &none   &none   &none           &none           &none           &none   &none   &none   &none
        &none           &to LYR_M_FUNC  &to LYR_M_SYM1  &to LYR_M_NAV1  &to LYR_M_UAT   &none   &none   &none           &none           &none           &none   &none   &none   &none
        &none           &none           &none           &none           &none           &none   &none   &none           &none           &none           &none   &none   &none   &none
        &none           &none           &none           &none           &none           &none   &none   &mcro_parens    &mcro_braces    &mcro_brackets  &none   &none   &none
        &none           &none           &none           &none           &none           &none   &none   &mcro_angle_brackets &none      &none           &none   &none
        &none           &none           &none           &none           &none           &none   &none   &none           &none           &none
        &none           &none           &none           &none           &none
      >;
    };

  /*
            ,.=:!!t3Z3z.,
          :tt:::tt333EE3
          Et:::ztt33EEEL @Ee.,      ..,
          ;tt:::tt333EE7 ;EEEEEEttttt33#
        :Et:::zt333EEQ. $EEEEEttttt33QL
        it::::tt333EEF @EEEEEEttttt33F
        ;3=*^```"*4EEV :EEEEEEttttt33@.
        ,.=::::!t=., ` @EEEEEEtttz33QF
      ;::::::::zt33)   "4EEEtttji3P*
      :t::::::::tt33.:Z3z..  `` ,..g.
      i::::::::zt33F AEEEtttt::::ztF
    ;:::::::::t33V ;EEEttttt::::t3
    E::::::::zt33L @EEEtttt::::z3F
    {3=*^```"*4E3) ;EEEtttt:::::tZ`
                ` :EEEEtttt::::z7
                    "VEzjt:;;z>*`
  */

    /* LAYER 6: LYR_W_BASE
      * Activated by the physical Win switch through Layer-0 position 77.
      * The minimum Windows base intentionally mirrors Layer 0's typing and
      * layer-access bindings until a Windows-specific binding map is approved.
    ┏━━━━━━━━━━━┳━━━━━━━━━┳━━━━━━━━━┳━━━━━━━━━┳━━━━━━━━━┳━━━━━━━━━┳━━━━━━━━━┳━━━━━━━━━┳━━━━━━━━━┳━━━━━━━━━┳━━━━━━━━━┳━━━━━━━━━┳━━━━━━━━━┳━━━━━━━━┓
    ┃           ┃         ┃         ┃         ┃         ┃         ┃         ┃         ┃         ┃         ┃         ┃         ┃         ┃        ┃
    ┃TAP: ESC   ┃   F1    ┃   F2    ┃   F3    ┃   F4    ┃   F5    ┃   F6    ┃    F7   ┃    F8   ┃    F9   ┃   F10   ┃   F11   ┃   F12   ┃  DEL   ┃
    ┃HOLD: CAPS ┃         ┃         ┃         ┃         ┃         ┃         ┃         ┃         ┃         ┃         ┃         ┃         ┃        ┃
    ┃           ┃         ┃         ┃         ┃         ┃         ┃         ┃         ┃         ┃         ┃         ┃         ┃         ┃        ┃
    ┣━━━━━━━┳━━━┻━━━━━┳━━━┻━━━━━┳━━━┻━━━━━┳━━━┻━━━━━┳━━━┻━━━━━┳━━━┻━━━━━┳━━━┻━━━━━┳━━━┻━━━━━┳━━━┻━━━━━┳━━━┻━━━━━┳━━━┻━━━━━┳━━━┻━━━━━┳━━━┻━━━━━━━━┫
    ┃   ~   ┃    !    ┃    @    ┃    #    ┃    $    ┃    %    ┃    ^    ┃    *    ┃    -    ┃    (    ┃    )    ┃    _    ┃    +    ┃            ┃
    ┃   `   ┃    1    ┃    2    ┃    3    ┃    4    ┃    5    ┃    6    ┃    7    ┃    8    ┃    9    ┃    0    ┃    -    ┃    =    ┃    BKSP    ┃
    ┃       ┃         ┃         ┃         ┃         ┃         ┃         ┃         ┃         ┃         ┃         ┃         ┃         ┃            ┃
    ┣━━━━━━━┻━━┳━━━━━━┻━━┳━━━━━━┻━━┳━━━━━━┻━━┳━━━━━━┻━━┳━━━━━━┻━━┳━━━━━━┻━━┳━━━━━━┻━━┳━━━━━━┻━━┳━━━━━━┻━━┳━━━━━━┻━━┳━━━━━━┻━━┳━━━━━━┻━━┳━━━━━━━━━┫
    ┃TAP: TAB  ┃         ┃         ┃         ┃         ┃         ┃         ┃         ┃         ┃         ┃         ┃    {    ┃    }    ┃    |    ┃
    ┃HOLD: HYPR┃    Q    ┃    W    ┃    E    ┃    R    ┃    T    ┃    Y    ┃    U    ┃    I    ┃    O    ┃    P    ┃    [    ┃    ]    ┃    \    ┃
    ┃          ┃         ┃         ┃         ┃         ┃         ┃         ┃         ┃         ┃         ┃         ┃         ┃         ┃         ┃
    ┣━━━━━━━━━━┻┳━━━━━━━━┻┳━━━━━━━━┻┳━━━━━━━━┻┳━━━━━━━━┻┳━━━━━━━━┻┳━━━━━━━━┻┳━━━━━━━━┻┳━━━━━━━━┻┳━━━━━━━━┻┳━━━━━━━━┻┳━━━━━━━━┻┳━━━━━━━━┻━━━━━━━━━┫
    ┃TAP=ESC    ┃ TAP=A   ┃ TAP=S   ┃ TAP=D   ┃ TAP=F   ┃ TAP=G   ┃ TAP=H   ┃ TAP=J   ┃ TAP=K   ┃ TAP=L   ┃ TAP=;/: ┃    "    ┃                  ┃
    ┃HOLD:MO(7) ┃ HLD=    ┃ HLD=    ┃ HLD=    ┃ HLD=    ┃ HLD=    ┃ HLD=    ┃ HLD=    ┃ HLD=    ┃ HLD=    ┃ HLD=    ┃    '    ┃      RETURN      ┃
    ┃           ┃  L_CTRL ┃  L_GUI  ┃  L_ALT  ┃ L_SHIFT ┃   MO(2) ┃   MO(2) ┃ R_SHIFT ┃  R_ALT  ┃  R_GUI  ┃  R_CTRL ┃         ┃                  ┃
    ┣━━━━━━━━━━━┻━━┳━━━━━━┻━━┳━━━━━━┻━━┳━━━━━━┻━━┳━━━━━━┻━━┳━━━━━━┻━━┳━━━━━━┻━━┳━━━━━━┻━━┳━━━━━━┻━━┳━━━━━━┻━━┳━━━━━━┻━━┳━━━━━━┻━━━━━━━━━━━━━━━━━━┫
    ┃              ┃         ┃         ┃         ┃         ┃         ┃         ┃         ┃    <    ┃    >    ┃    ?    ┃                         ┃
    ┃   L_SHIFT    ┃    Z    ┃    X    ┃    C    ┃    V    ┃    B    ┃   N     ┃    M    ┃    ,    ┃    .    ┃    /    ┃        R_SHIFT          ┃
    ┃              ┃         ┃         ┃         ┃         ┃         ┃         ┃         ┃         ┃         ┃         ┃                         ┃
    ┣━━━━━━━━━━━┳━━┻━━━━━━━┳━┻━━━━━━━━━╋━━━━━━━━━┻━━━━━━━━━┻━━━━━━━━━┻━━━━━━━━━┻━━━━━━━━━╋━━━━━━━━━┻━━━━┳━━━━┻━━━━━┳━┳━┻━━━━━━┳━━━━━━━━━┳━━━━━━━━┫
    ┃           ┃          ┃           ┃                                                 ┃              ┃TAP: OSL( ┃ ┃        ┃    ↑    ┃        ┃
    ┃  L_CTRL   ┃  L_GUI   ┃   L_ALT   ┃             * &lt LYR_W_NAV1 SPACE *            ┃    R_ALT     ┃    11)   ┃ ┃    ←   ┣━━━━━━━━━┫   →    ┃
    ┃           ┃          ┃           ┃                                                 ┃              ┃HOLD:MO(7)┃ ┃        ┃    ↓    ┃        ┃
    ┗━━━━━━━━━━━┻━━━━━━━━━━┻━━━━━━━━━━━┻━━━━━━━━━━━━━━━━━━━━━━━━━━━━━━━━━━━━━━━━━━━━━━━━━┻━━━━━━━━━━━━━━┻━━━━━━━━━━┛ ┗━━━━━━━━┻━━━━━━━━━┻━━━━━━━━┛
      */
    layer_w_base {
      bindings = <
        //ESC                     //f1          //f2         //f3                  //f4          //f5              //f6              //f7          //f8          //f9         //f10            //f11      //f12      //DEL
        &esc_caps CLCK ESC        &kp F1        &kp F2       &kp F3                &kp F4        &kp F5            &kp F6            &kp F7        &kp F8        &kp F9       &kp F10          &kp F11    &kp F12    &kp DEL
        &kp GRAVE                 &kp N1        &kp N2       &kp N3                &kp N4        &kp N5            &kp N6            &kp N7        &kp N8        &kp N9       &kp N0           &kp MINUS  &kp EQUAL  &kp BSPC
        &mt LC(LS(LG(LALT))) TAB  &kp Q         &kp W        &kp E                 &kp R         &kp T             &kp Y             &kp U         &kp I         &kp O        &kp P            &kp LBKT   &kp RBKT   &lt LYR_W_NAV1 BSLH
        &lt LYR_W_FUNC ESC        &lhm LCTRL A  &lhm LGUI S  &lhm LALT D           &lhm LSHFT F  &lt LYR_W_SYM1 G  &lt LYR_W_SYM1 H  &rhm RSHFT J  &rhm RALT K   &rhm RGUI L  &rhm RCTRL SEMI  &kp SQT               &kp RET
        &kp LSHFT                 &lt LYR_W_MCRO Z  &kp X    &kp C                 &kp V         &kp B             &kp N             &kp M         &kp COMMA     &kp DOT      &lt LYR_W_MCRO FSLH  &kp RSHFT
        &kp LCTRL                 &uc LCMD      &uc LALT     &lt LYR_W_NAV1 SPACE                &uc RALT          &fn_layer_access  LYR_W_FUNC LYR_W_MCRO       &kp LEFT     &kp UP           &kp DOWN   &kp RIGHT
        &none                     &none         &none        &none                 &none
      >;
    };

    /* WINDOWS LAYER 7: LYR_W_FUNC
    ┏━━━━━━━━━━━┳━━━━━━━━━┳━━━━━━━━━┳━━━━━━━━━┳━━━━━━━━━┳━━━━━━━━━┳━━━━━━━━━┳━━━━━━━━━┳━━━━━━━━━┳━━━━━━━━━┳━━━━━━━━━┳━━━━━━━━━┳━━━━━━━━━┳━━━━━━━━┓
    ┃           ┃         ┃         ┃         ┃         ┃VOQUILL  ┃MIC-MUTE:┃ PREVIOUS┃ PLAY/   ┃   NEXT  ┃         ┃         ┃         ┃        ┃
    ┃TO(LYR_W_  ┃ Bright- ┃ Bright+ ┃ WIN+TAB ┃ALT+SPACE┃   V+N   ┃CTRL+ALT+┃  TRACK  ┃  PAUSE  ┃  TRACK  ┃   MUTE  ┃   Vol-  ┃  Vol+   ┃   DEL  ┃
    ┃   BASE)   ┃         ┃         ┃         ┃         ┃         ┃    M    ┃         ┃         ┃         ┃         ┃         ┃         ┃        ┃
    ┣━━━━━━━┳━━━┻━━━━━┳━━━┻━━━━━┳━━━┻━━━━━┳━━━┻━━━━━┳━━━┻━━━━━┳━━━┻━━━━━┳━━━┻━━━━━┳━━━┻━━━━━┳━━━┻━━━━━┳━━━┻━━━━━┳━━━┻━━━━━┳━━━┻━━━━━┳━━━┻━━━━━━━━┫
    ┃       ┃TAP:BT1  ┃TAP:BT2  ┃TAP:BT3  ┃  2.4G   ┃         ┃         ┃ NUMPAD  ┃ NUMPAD  ┃ NUMPAD  ┃ NUMPAD  ┃         ┃         ┃            ┃
    ┃    ▼  ┃DBL:PAIR1┃DBL:PAIR2┃DBL:PAIR3┃  PAIR   ┃    ▼    ┃    ▼    ┃    ×    ┃    ÷    ┃    +    ┃    −    ┃   Boot  ┃  Search ┃     ▼      ┃
    ┃       ┃         ┃         ┃         ┃         ┃         ┃         ┃         ┃         ┃         ┃         ┃         ┃         ┃            ┃
    ┣━━━━━━━┻━━┳━━━━━━┻━━┳━━━━━━┻━━┳━━━━━━┻━━┳━━━━━━┻━━┳━━━━━━┻━━┳━━━━━━┻━━┳━━━━━━┻━━┳━━━━━━┻━━┳━━━━━━┻━━┳━━━━━━┻━━┳━━━━━━┻━━┳━━━━━━┻━━┳━━━━━━━━━┫
    ┃          ┃         ┃         ┃         ┃         ┃         ┃         ┃ NUMPAD  ┃ NUMPAD  ┃ NUMPAD  ┃         ┃         ┃         ┃         ┃
    ┃     ▼    ┃    ▼    ┃    ▼    ┃    ▼    ┃    ▼    ┃    ▼    ┃ DELETE  ┃    7    ┃    8    ┃    9    ┃BACKSPACE┃     ▼   ┃    ▼    ┃ LGS(X)  ┃
    ┃          ┃         ┃         ┃         ┃         ┃         ┃         ┃         ┃         ┃         ┃         ┃         ┃         ┃         ┃
    ┣━━━━━━━━━━┻┳━━━━━━━━┻┳━━━━━━━━┻┳━━━━━━━━┻┳━━━━━━━━┻┳━━━━━━━━┻┳━━━━━━━━┻┳━━━━━━━━┻┳━━━━━━━━┻┳━━━━━━━━┻┳━━━━━━━━┻┳━━━━━━━━┻┳━━━━━━━━┻━━━━━━━━━┫
    ┃           ┃         ┃         ┃         ┃         ┃         ┃         ┃ NUMPAD  ┃ NUMPAD  ┃ NUMPAD  ┃         ┃         ┃                  ┃
    ┃     ▼     ┃  L_CTRL ┃  L_GUI  ┃  L_ALT  ┃ L_SHIFT ┃     ▼   ┃   TAB   ┃    4    ┃    5    ┃    6    ┃  ENTER  ┃     ▼   ┃         ▼        ┃
    ┃           ┃         ┃         ┃         ┃         ┃         ┃         ┃         ┃         ┃         ┃         ┃         ┃                  ┃
    ┣━━━━━━━━━━━┻━━┳━━━━━━┻━━┳━━━━━━┻━━┳━━━━━━┻━━┳━━━━━━┻━━┳━━━━━━┻━━┳━━━━━━┻━━┳━━━━━━┻━━┳━━━━━━┻━━┳━━━━━━┻━━┳━━━━━━┻━━┳━━━━━━┻━━━━━━━━━━━━━━━━━━┫
    ┃              ┃         ┃         ┃         ┃         ┃         ┃         ┃ NUMPAD  ┃ NUMPAD  ┃ NUMPAD  ┃ NUMPAD  ┃                         ┃
    ┃       ▼      ┃     ▼   ┃     ▼   ┃     ▼   ┃    ▼    ┃    ▼    ┃    ,    ┃    1    ┃    2    ┃    3    ┃    .    ┃         WIN+DOT         ┃
    ┃              ┃         ┃         ┃         ┃         ┃         ┃         ┃         ┃         ┃         ┃         ┃                         ┃
    ┣━━━━━━━━━━━┳━━┻━━━━━━━┳━┻━━━━━━━━━╋━━━━━━━━━┻━━━━━━━━━┻━━━━━━━━━┻━━━━━━━━━┻━━━━━━━━━╋━━━━━━━━━┻━━━━┳━━━━┻━━━━━┳━┳━┻━━━━━━┳━━━━━━━━━┳━━━━━━━━┫
    ┃           ┃          ┃           ┃                     NUMPAD                      ┃              ┃          ┃ ┃        ┃  PgUp   ┃        ┃
    ┃      ▼    ┃     ▼    ┃     ▼     ┃                        0                        ┃       ▼      ┃     ▼    ┃ ┃  Home  ┣━━━━━━━━━┫   End  ┃
    ┃           ┃          ┃           ┃                                                 ┃              ┃          ┃ ┃        ┃  PgDn   ┃        ┃
    ┗━━━━━━━━━━━┻━━━━━━━━━━┻━━━━━━━━━━━┻━━━━━━━━━━━━━━━━━━━━━━━━━━━━━━━━━━━━━━━━━━━━━━━━━┻━━━━━━━━━━━━━━┻━━━━━━━━━━┛ ┗━━━━━━━━┻━━━━━━━━━┻━━━━━━━━┛
     */
    layer_w_func {
      bindings = <
        //ESC           //F1                  //F2                  //F3         //f4           //f5        //f6           //f7             //f8              //f9         //f10         //f11                       //f12            //DEL
        &to LYR_W_BASE  &kp C_BRIGHTNESS_DEC  &kp C_BRIGHTNESS_INC  &uc LG(TAB)  &uc LG(E)      &kp C_AC_SEARCH  &uc LG(L)      &kp C_PREVIOUS   &kp C_PLAY_PAUSE  &kp C_NEXT   &kp C_MUTE    &kp C_VOLUME_DOWN           &kp C_VOLUME_UP  &kp DEL
        &trans          &td_bt_0 0            &td_bt_1 0            &td_bt_2 0   &out OUT_24G   &trans      &trans         &kp KP_MULTIPLY  &kp KP_DIVIDE     &kp KP_PLUS  &kp KP_MINUS  &long_press_bootloader 0 0  &kp C_AC_SEARCH  &trans
        &trans          &trans                &trans                &trans       &trans         &trans      &kp DEL        &kp KP_N7        &kp KP_N8         &kp KP_N9    &kp BSPC      &trans                      &trans           &uc LG(LS(S))
        &trans          &kp LCTRL             &kp LGUI              &kp LALT     &kp LSHFT      &trans      &kp TAB        &kp KP_N4        &kp KP_N5         &kp KP_N6    &kp RET       &trans                      &trans
        &trans          &trans                &trans                &trans       &trans         &trans      &kp COMMA      &kp KP_N1        &kp KP_N2         &kp KP_N3    &kp KP_DOT    &uc LG(DOT)
        &trans          &trans                &trans                &kp KP_N0    &trans         &trans      &kp HOME       &kp PG_UP        &kp PG_DN         &kp END
        &none           &none                 &none                 &none        &none
      >;
    };

    /* WINDOWS LAYER 8: LYR_W_SYM1 — physical binding illustration
    ┏━━━━━━━━━━━┳━━━━━━━━━┳━━━━━━━━━┳━━━━━━━━━┳━━━━━━━━━┳━━━━━━━━━┳━━━━━━━━━┳━━━━━━━━━┳━━━━━━━━━┳━━━━━━━━━┳━━━━━━━━━┳━━━━━━━━━┳━━━━━━━━━┳━━━━━━━━┓
    ┃           ┃         ┃         ┃         ┃         ┃         ┃         ┃         ┃         ┃         ┃         ┃         ┃         ┃        ┃
    ┃TO(LYR_W_  ┃   F13   ┃   F14   ┃   F15   ┃   F16   ┃   F17   ┃   F18   ┃   F19   ┃   F20   ┃   F21   ┃   F22   ┃   F23   ┃   F24   ┃   ▼    ┃
    ┃   BASE)   ┃         ┃         ┃         ┃         ┃         ┃         ┃         ┃         ┃         ┃         ┃         ┃         ┃        ┃
    ┣━━━━━━━┳━━━┻━━━━━┳━━━┻━━━━━┳━━━┻━━━━━┳━━━┻━━━━━┳━━━┻━━━━━┳━━━┻━━━━━┳━━━┻━━━━━┳━━━┻━━━━━┳━━━┻━━━━━┳━━━┻━━━━━┳━━━┻━━━━━┳━━━┻━━━━━┳━━━┻━━━━━━━━┫
    ┃       ┃         ┃         ┃         ┃         ┃         ┃         ┃         ┃         ┃         ┃         ┃         ┃         ┃            ┃
    ┃   ▼   ┃    ▼    ┃    ▼    ┃    ▼    ┃    ▼    ┃    ▼    ┃    ▼    ┃    ▼    ┃    ▼    ┃    ▼    ┃ LC(N0)  ┃LC(MINUS)┃LC(EQUAL)┃     ▼      ┃
    ┃       ┃         ┃         ┃         ┃         ┃         ┃         ┃         ┃         ┃         ┃         ┃         ┃         ┃            ┃
    ┣━━━━━━━┻━━┳━━━━━━┻━━┳━━━━━━┻━━┳━━━━━━┻━━┳━━━━━━┻━━┳━━━━━━┻━━┳━━━━━━┻━━┳━━━━━━┻━━┳━━━━━━┻━━┳━━━━━━┻━━┳━━━━━━┻━━┳━━━━━━┻━━┳━━━━━━┻━━┳━━━━━━━━━┫
    ┃          ┃         ┃         ┃         ┃         ┃         ┃         ┃         ┃         ┃         ┃         ┃         ┃         ┃S(KC_    ┃
    ┃    [`]   ┃   [!]   ┃   [@]   ┃   [#]   ┃   [$]   ┃   [%]   ┃   [^]   ┃   [&]   ┃   [*]   ┃   [-]   ┃   [=]   ┃    ▼    ┃    ▼    ┃  BSLS)  ┃
    ┃          ┃         ┃         ┃         ┃         ┃         ┃         ┃         ┃         ┃         ┃         ┃         ┃         ┃         ┃
    ┣━━━━━━━━━━┻┳━━━━━━━━┻┳━━━━━━━━┻┳━━━━━━━━┻┳━━━━━━━━┻┳━━━━━━━━┻┳━━━━━━━━┻┳━━━━━━━━┻┳━━━━━━━━┻┳━━━━━━━━┻┳━━━━━━━━┻┳━━━━━━━━┻┳━━━━━━━━┻━━━━━━━━━┫
    ┃           ┃         ┃         ┃         ┃         ┃    *    ┃   *     ┃ 1TAP: ( ┃ 1TAP: { ┃ 1TAP: [ ┃         ┃         ┃                  ┃
    ┃    [~]    ┃  L_CTRL ┃  L_GUI  ┃  L_ALT  ┃ L_SHIFT ┃  SYMBOL ┃ SYMBOL  ┃ 2TAP: ) ┃ 2TAP: } ┃ 2TAP: ] ┃    ▼    ┃    ▼    ┃       [=]        ┃
    ┃           ┃         ┃         ┃         ┃         ┃    *    ┃   *     ┃         ┃         ┃         ┃         ┃         ┃                  ┃
    ┣━━━━━━━━━━━┻━━┳━━━━━━┻━━┳━━━━━━┻━━┳━━━━━━┻━━┳━━━━━━┻━━┳━━━━━━┻━━┳━━━━━━┻━━┳━━━━━━┻━━┳━━━━━━┻━━┳━━━━━━┻━━┳━━━━━━┻━━┳━━━━━━┻━━━━━━━━━━━━━━━━━━┫
    ┃              ┃         ┃         ┃         ┃         ┃         ┃         ┃ 1TAP: < ┃         ┃         ┃         ┃                         ┃
    ┃       ▼      ┃    ▼    ┃    ▼    ┃    ▼    ┃    ▼    ┃    ▼    ┃    ▼    ┃ 2TAP: > ┃    ▼    ┃    ▼    ┃    ▼    ┃         Emoji-m         ┃
    ┃              ┃         ┃         ┃         ┃         ┃         ┃         ┃         ┃         ┃         ┃         ┃                         ┃
    ┣━━━━━━━━━━━┳━━┻━━━━━━━┳━┻━━━━━━━━━╋━━━━━━━━━┻━━━━━━━━━┻━━━━━━━━━┻━━━━━━━━━┻━━━━━━━━━╋━━━━━━━━━┻━━━━┳━━━━┻━━━━━┳━┳━┻━━━━━━┳━━━━━━━━━┳━━━━━━━━┫
    ┃           ┃          ┃           ┃                                                 ┃              ┃          ┃ ┃        ┃    ↑    ┃        ┃
    ┃     ▼     ┃    ▼     ┃     ▼     ┃                         ▼                       ┃       ▼      ┃     ▼    ┃ ┃    ←   ┣━━━━━━━━━┫   →    ┃
    ┃           ┃          ┃           ┃                                                 ┃              ┃          ┃ ┃        ┃    ↓    ┃        ┃
    ┗━━━━━━━━━━━┻━━━━━━━━━━┻━━━━━━━━━━━┻━━━━━━━━━━━━━━━━━━━━━━━━━━━━━━━━━━━━━━━━━━━━━━━━━┻━━━━━━━━━━━━━━┻━━━━━━━━━━┛ ┗━━━━━━━━┻━━━━━━━━━┻━━━━━━━━┛
     */
    layer_w_sym1 {
      bindings = <
        //ESC           //f1       //f2      //f3      //f4       //f5       //f6       //f7              //f8              //f9              //f10          //f11          //f12          //DEL
        &to LYR_W_BASE  &kp F13    &kp F14   &kp F15   &kp F16    &kp F17    &kp F18    &kp F19           &kp F20           &kp F21           &kp F22        &kp F23        &kp F24        &trans
        &trans          &trans     &trans    &trans    &trans     &trans     &trans     &trans            &trans            &trans            &uc LC(N0)     &uc LC(MINUS)  &uc LC(EQUAL)  &trans
        &kp GRAVE       &kp EXCL   &kp AT    &kp HASH  &kp DLLR   &kp PRCNT  &kp CARET  &kp AMPS          &kp ASTERISK      &kp MINUS         &kp EQUAL      &trans         &trans         &trans
        &kp TILDE       &kp LCTRL  &kp LGUI  &kp LALT  &kp LSHFT  &none      &none      &td_sym_parens 0  &td_sym_braces 0  &td_sym_brackets 0 &trans         &trans         &kp EQUAL
        &trans          &trans     &trans    &trans    &trans     &trans     &trans     &td_sym_angle_brackets 0            &trans            &trans         &trans         &uc LG(DOT)
        &trans          &trans     &trans    &trans    &trans     &trans     &trans     &trans            &trans            &trans
        &none           &none      &none     &none     &none
      >;
    };

    /* WINDOWS LAYER 9: LYR_W_NAV1 — physical binding illustration
     * [Esc F1..F12 Del] => W base, F13..F24, transparent Del.
     * [Tab Q..P [ ] \\] => Alt+F4, Ctrl+W, mouse wheel, Delete/Up/Backspace, mouse directions.
     * [Caps A..; Enter] => inert Caps, modifiers, Home/Left/Down/Right/End.
     * [Shift Z X C V B N M , . / RShift] => Ctrl+Z/X/C/V/B, PgUp/PgDn, tab and slash chords.
     * [Ctrl Alt Win Space Alt Fn arrows] => mouse-speed 1/2/3, inert space/alt/fn, arrow cluster.

    ┏━━━━━━━━━━━┳━━━━━━━━━┳━━━━━━━━━┳━━━━━━━━━┳━━━━━━━━━┳━━━━━━━━━┳━━━━━━━━━┳━━━━━━━━━┳━━━━━━━━━┳━━━━━━━━━┳━━━━━━━━━┳━━━━━━━━━┳━━━━━━━━━┳━━━━━━━━┓
    ┃           ┃         ┃         ┃         ┃         ┃         ┃         ┃         ┃         ┃         ┃         ┃         ┃         ┃        ┃
    ┃TO(LYR_W_  ┃   F13   ┃   F14   ┃   F15   ┃   F16   ┃   F17   ┃   F18   ┃   F19   ┃   F20   ┃   F21   ┃   F22   ┃   F23   ┃   F24   ┃   ▼    ┃
    ┃   BASE)   ┃         ┃         ┃         ┃         ┃         ┃         ┃         ┃         ┃         ┃         ┃         ┃         ┃        ┃
    ┣━━━━━━━┳━━━┻━━━━━┳━━━┻━━━━━┳━━━┻━━━━━┳━━━┻━━━━━┳━━━┻━━━━━┳━━━┻━━━━━┳━━━┻━━━━━┳━━━┻━━━━━┳━━━┻━━━━━┳━━━┻━━━━━┳━━━┻━━━━━┳━━━┻━━━━━┳━━━┻━━━━━━━━┫
    ┃       ┃         ┃         ┃         ┃         ┃         ┃         ┃         ┃         ┃         ┃         ┃         ┃         ┃            ┃
    ┃   ▼   ┃    ▼    ┃    ▼    ┃    #    ┃    ▼    ┃   MW ↓  ┃    ▼    ┃    ▼    ┃  SPACE  ┃    ▼    ┃  MBtn1  ┃ Mouse ↑ ┃  MBtn2  ┃     ▼      ┃
    ┃       ┃         ┃         ┃         ┃         ┃         ┃         ┃         ┃         ┃         ┃         ┃         ┃         ┃            ┃
    ┣━━━━━━━┻━━┳━━━━━━┻━━┳━━━━━━┻━━┳━━━━━━┻━━┳━━━━━━┻━━┳━━━━━━┻━━┳━━━━━━┻━━┳━━━━━━┻━━┳━━━━━━┻━━┳━━━━━━┻━━┳━━━━━━┻━━┳━━━━━━┻━━┳━━━━━━┻━━┳━━━━━━━━━┫
    ┃          ┃         ┃         ┃         ┃         ┃         ┃         ┃         ┃         ┃         ┃         ┃         ┃         ┃         ┃
    ┃    ▼     ┃ LA(F4)  ┃ LC(W)   ┃  MW ←   ┃  MW ↑   ┃  MW →   ┃  LC(Y)  ┃   Del   ┃    ↑    ┃  Bksp   ┃ Mouse ← ┃ Mouse ↓ ┃ Mouse → ┃    ▼    ┃
    ┃          ┃         ┃         ┃         ┃         ┃         ┃         ┃         ┃         ┃         ┃         ┃         ┃         ┃         ┃
    ┣━━━━━━━━━━┻┳━━━━━━━━┻┳━━━━━━━━┻┳━━━━━━━━┻┳━━━━━━━━┻┳━━━━━━━━┻┳━━━━━━━━┻┳━━━━━━━━┻┳━━━━━━━━┻┳━━━━━━━━┻┳━━━━━━━━┻┳━━━━━━━━┻┳━━━━━━━━┻━━━━━━━━━┫
    ┃           ┃         ┃         ┃         ┃         ┃         ┃         ┃         ┃         ┃         ┃         ┃         ┃                  ┃
    ┃     ▼     ┃  L_CTRL ┃  L_GUI  ┃  L_ALT  ┃ L_SHIFT ┃  SPACE  ┃   Home  ┃    ←    ┃    ↓    ┃    →    ┃   End   ┃    ▼    ┃        ▼         ┃
    ┃           ┃         ┃         ┃         ┃         ┃         ┃         ┃         ┃         ┃         ┃         ┃         ┃                  ┃
    ┣━━━━━━━━━━━┻━━┳━━━━━━┻━━┳━━━━━━┻━━┳━━━━━━┻━━┳━━━━━━┻━━┳━━━━━━┻━━┳━━━━━━┻━━┳━━━━━━┻━━┳━━━━━━┻━━┳━━━━━━┻━━┳━━━━━━┻━━┳━━━━━━┻━━━━━━━━━━━━━━━━━━┫
    ┃              ┃         ┃         ┃         ┃1T:LC(V) ┃         ┃         ┃         ┃         ┃         ┃         ┃                         ┃
    ┃      ▼       ┃  LC(Z)  ┃  LC(X)  ┃  LC(C)  ┃2T:LG(V) ┃  LC(B)  ┃  PgUp   ┃  PgDn   ┃LCS(TAB) ┃ LC(TAB) ┃ LCS(/)  ┃           ▼             ┃
    ┃              ┃         ┃         ┃         ┃3T:LCS(V)┃         ┃         ┃         ┃         ┃         ┃         ┃                         ┃
    ┣━━━━━━━━━━━┳━━┻━━━━━━━┳━┻━━━━━━━━━╋━━━━━━━━━┻━━━━━━━━━┻━━━━━━━━━┻━━━━━━━━━┻━━━━━━━━━╋━━━━━━━━━┻━━━━┳━━━━┻━━━━━┳━┳━┻━━━━━━┳━━━━━━━━━┳━━━━━━━━┫
    ┃           ┃          ┃           ┃                                                 ┃              ┃          ┃ ┃        ┃    ↑    ┃        ┃
    ┃   MSPD1   ┃   MSPD2  ┃   MSPD3   ┃                                                 ┃       ▼      ┃     ▼    ┃ ┃    ←   ┣━━━━━━━━━┫   →    ┃
    ┃           ┃          ┃           ┃                                                 ┃              ┃          ┃ ┃        ┃    ↓    ┃        ┃
    ┗━━━━━━━━━━━┻━━━━━━━━━━┻━━━━━━━━━━━┻━━━━━━━━━━━━━━━━━━━━━━━━━━━━━━━━━━━━━━━━━━━━━━━━━┻━━━━━━━━━━━━━━┻━━━━━━━━━━┛ ┗━━━━━━━━┻━━━━━━━━━┻━━━━━━━━┛
    */
    layer_w_nav1 {
      bindings = <
        &to LYR_W_BASE     &kp F13            &kp F14            &kp F15               &kp F16             &kp F17                &kp F18     &kp F19          &kp F20      &kp F21           &kp F22             &kp F23         &kp F24             &trans
        &trans             &trans             &trans             &kp HASH              &trans              &uc MOUSE_WHEEL_DOWN   &trans      &trans           &kp SPACE    &trans            &uc MOUSE_BUTTON_1  &uc MOUSE_UP    &uc MOUSE_BUTTON_2  &trans
        &trans             &uc LA(F4)         &uc LC(W)          &uc MOUSE_WHEEL_LEFT  &uc MOUSE_WHEEL_UP  &uc MOUSE_WHEEL_RIGHT  &uc LC(Y)   &kp DEL          &kp UP       &kp BSPC          &uc MOUSE_LEFT      &uc MOUSE_DOWN  &uc MOUSE_RIGHT     &trans
        &trans             &kp LCTRL          &kp LGUI           &kp LALT  &kp LSHFT   &kp SPACE           &kp HOME               &kp LEFT    &kp DOWN         &kp RIGHT    &kp END           &trans              &trans
        &trans             &uc LC(Z)          &uc LC(X)          &uc LC(C)  &uc LC(V)  &uc LC(B)           &kp PG_UP              &kp PG_DN   &uc LC(LS(TAB))  &uc LC(TAB)  &uc LC(LS(FSLH))  &trans
        &uc MOUSE_SPEED_1  &uc MOUSE_SPEED_2  &uc MOUSE_SPEED_3  &none                 &trans              &trans                 &kp LEFT    &kp UP           &kp DOWN     &kp RIGHT
        &none  &none  &none  &none  &none
      >;
    };

    /* WINDOWS LAYER 10: LYR_W_UAT — illustration: [Esc] TO(W base); every other physical position is inert.
    **Description:** Reserved UAT layer. Escape returns to Layer 0; every other position is inert.
    ┏━━━━━━━━━━━┳━━━━━━━━━┳━━━━━━━━━┳━━━━━━━━━┳━━━━━━━━━┳━━━━━━━━━┳━━━━━━━━━┳━━━━━━━━━┳━━━━━━━━━┳━━━━━━━━━┳━━━━━━━━━┳━━━━━━━━━┳━━━━━━━━━┳━━━━━━━━┓
    ┃           ┃         ┃         ┃         ┃         ┃         ┃         ┃         ┃         ┃         ┃         ┃         ┃         ┃        ┃
    ┃TO(LYR_W_  ┃         ┃         ┃         ┃         ┃         ┃         ┃         ┃         ┃         ┃         ┃         ┃         ┃        ┃
    ┃   BASE)   ┃         ┃         ┃         ┃         ┃         ┃         ┃         ┃         ┃         ┃         ┃         ┃         ┃        ┃
    ┣━━━━━━━┳━━━┻━━━━━┳━━━┻━━━━━┳━━━┻━━━━━┳━━━┻━━━━━┳━━━┻━━━━━┳━━━┻━━━━━┳━━━┻━━━━━┳━━━┻━━━━━┳━━━┻━━━━━┳━━━┻━━━━━┳━━━┻━━━━━┳━━━┻━━━━━┳━━━┻━━━━━━━━┫
    ┃       ┃         ┃         ┃         ┃         ┃         ┃         ┃         ┃         ┃         ┃         ┃         ┃         ┃            ┃
    ┃       ┃         ┃         ┃         ┃         ┃         ┃         ┃         ┃         ┃         ┃         ┃         ┃         ┃            ┃
    ┃       ┃         ┃         ┃         ┃         ┃         ┃         ┃         ┃         ┃         ┃         ┃         ┃         ┃            ┃
    ┣━━━━━━━┻━━┳━━━━━━┻━━┳━━━━━━┻━━┳━━━━━━┻━━┳━━━━━━┻━━┳━━━━━━┻━━┳━━━━━━┻━━┳━━━━━━┻━━┳━━━━━━┻━━┳━━━━━━┻━━┳━━━━━━┻━━┳━━━━━━┻━━┳━━━━━━┻━━┳━━━━━━━━━┫
    ┃          ┃         ┃         ┃         ┃         ┃         ┃         ┃         ┃         ┃         ┃         ┃         ┃         ┃         ┃
    ┃          ┃         ┃         ┃         ┃         ┃         ┃         ┃         ┃         ┃         ┃         ┃         ┃         ┃         ┃
    ┃          ┃         ┃         ┃         ┃         ┃         ┃         ┃         ┃         ┃         ┃         ┃         ┃         ┃         ┃
    ┣━━━━━━━━━━┻┳━━━━━━━━┻┳━━━━━━━━┻┳━━━━━━━━┻┳━━━━━━━━┻┳━━━━━━━━┻┳━━━━━━━━┻┳━━━━━━━━┻┳━━━━━━━━┻┳━━━━━━━━┻┳━━━━━━━━┻┳━━━━━━━━┻┳━━━━━━━━┻━━━━━━━━━┫
    ┃           ┃         ┃         ┃         ┃         ┃         ┃         ┃         ┃         ┃         ┃         ┃         ┃                  ┃
    ┃           ┃         ┃         ┃         ┃         ┃         ┃         ┃         ┃         ┃         ┃         ┃         ┃                  ┃
    ┃           ┃         ┃         ┃         ┃         ┃         ┃         ┃         ┃         ┃         ┃         ┃         ┃                  ┃
    ┣━━━━━━━━━━━┻━━┳━━━━━━┻━━┳━━━━━━┻━━┳━━━━━━┻━━┳━━━━━━┻━━┳━━━━━━┻━━┳━━━━━━┻━━┳━━━━━━┻━━┳━━━━━━┻━━┳━━━━━━┻━━┳━━━━━━┻━━┳━━━━━━┻━━━━━━━━━━━━━━━━━━┫
    ┃              ┃         ┃         ┃         ┃         ┃         ┃         ┃         ┃         ┃         ┃         ┃                         ┃
    ┃              ┃         ┃         ┃         ┃         ┃         ┃         ┃         ┃         ┃         ┃         ┃                         ┃
    ┃              ┃         ┃         ┃         ┃         ┃         ┃         ┃         ┃         ┃         ┃         ┃                         ┃
    ┣━━━━━━━━━━━┳━━┻━━━━━━━┳━┻━━━━━━━━━╋━━━━━━━━━┻━━━━━━━━━┻━━━━━━━━━┻━━━━━━━━━┻━━━━━━━━━╋━━━━━━━━━┻━━━━┳━━━━┻━━━━━┳━┳━┻━━━━━━┳━━━━━━━━━┳━━━━━━━━┫
    ┃           ┃          ┃           ┃                                                 ┃              ┃          ┃ ┃        ┃         ┃        ┃
    ┃           ┃          ┃           ┃                                                 ┃              ┃          ┃ ┃        ┣━━━━━━━━━┫        ┃
    ┃           ┃          ┃           ┃                                                 ┃              ┃          ┃ ┃        ┃         ┃        ┃
    ┗━━━━━━━━━━━┻━━━━━━━━━━┻━━━━━━━━━━━┻━━━━━━━━━━━━━━━━━━━━━━━━━━━━━━━━━━━━━━━━━━━━━━━━━┻━━━━━━━━━━━━━━┻━━━━━━━━━━┛ ┗━━━━━━━━┻━━━━━━━━━┻━━━━━━━━┛
    */

    layer_w_uat {
      bindings = <
        //ESC           //f1    //f2    //f3    //f4    //f5    //f6    //f7    //f8    //f9    //f10   //f11   //f12   //DEL
        &to LYR_W_BASE  &none   &none   &none   &none   &none   &none   &none   &none   &none   &none   &none   &none   &none
        &none           &none   &none   &none   &none   &none   &none   &none   &none   &none   &none   &none   &none   &none
        &none           &none   &none   &none   &none   &none   &none   &none   &none   &none   &none   &none   &none   &none
        &none           &none   &none   &none   &none   &none   &none   &none   &none   &none   &none   &none   &none
        &none           &none   &none   &none   &none   &none   &none   &none   &none   &none   &none   &none
        &none           &none   &none   &none   &none   &none   &none   &none   &none   &none
        &none           &none   &none   &none   &none
      >;
    };

    /* WINDOWS LAYER 11: LYR_W_MCRO (developer macro / Fn selector / Hold Z or /)
     * [Esc] returns to W base. [1 2 3 4] persistently select W Func/Sym/Nav/UAT.
     * J, K, L, M emit auto-closing brackets with cursor centering.
     * Every remaining physical key, including all five direct controls, is inert.
    ┏━━━━━━━━━━━┳━━━━━━━━━┳━━━━━━━━━┳━━━━━━━━━┳━━━━━━━━━┳━━━━━━━━━┳━━━━━━━━━┳━━━━━━━━━┳━━━━━━━━━┳━━━━━━━━━┳━━━━━━━━━┳━━━━━━━━━┳━━━━━━━━━┳━━━━━━━━┓
    ┃           ┃         ┃         ┃         ┃         ┃         ┃         ┃         ┃         ┃         ┃         ┃         ┃         ┃        ┃
    ┃TO(LYR_W_  ┃         ┃         ┃         ┃         ┃         ┃         ┃         ┃         ┃         ┃         ┃         ┃         ┃        ┃
    ┃   BASE)   ┃         ┃         ┃         ┃         ┃         ┃         ┃         ┃         ┃         ┃         ┃         ┃         ┃        ┃
    ┣━━━━━━━┳━━━┻━━━━━┳━━━┻━━━━━┳━━━┻━━━━━┳━━━┻━━━━━┳━━━┻━━━━━┳━━━┻━━━━━┳━━━┻━━━━━┳━━━┻━━━━━┳━━━┻━━━━━┳━━━┻━━━━━┳━━━┻━━━━━┳━━━┻━━━━━┳━━━┻━━━━━━━━┫
    ┃       ┃TO(LAYER_┃TO(LAYER_┃TO(LAYER_┃TO(LAYER_┃         ┃         ┃         ┃         ┃         ┃         ┃         ┃         ┃            ┃
    ┃       ┃ W_FUNC) ┃ W_SYM1) ┃ W_NAV1) ┃ W_UAT)  ┃         ┃         ┃         ┃         ┃         ┃         ┃         ┃         ┃            ┃
    ┃       ┃         ┃         ┃         ┃         ┃         ┃         ┃         ┃         ┃         ┃         ┃         ┃         ┃            ┃
    ┣━━━━━━━┻━━┳━━━━━━┻━━┳━━━━━━┻━━┳━━━━━━┻━━┳━━━━━━┻━━┳━━━━━━┻━━┳━━━━━━┻━━┳━━━━━━┻━━┳━━━━━━┻━━┳━━━━━━┻━━┳━━━━━━┻━━┳━━━━━━┻━━┳━━━━━━┻━━┳━━━━━━━━━┫
    ┃          ┃         ┃         ┃         ┃         ┃         ┃         ┃         ┃         ┃         ┃         ┃         ┃         ┃         ┃
    ┃          ┃         ┃         ┃         ┃         ┃         ┃         ┃         ┃         ┃         ┃         ┃         ┃         ┃         ┃
    ┃          ┃         ┃         ┃         ┃         ┃         ┃         ┃         ┃         ┃         ┃         ┃         ┃         ┃         ┃
    ┣━━━━━━━━━━┻┳━━━━━━━━┻┳━━━━━━━━┻┳━━━━━━━━┻┳━━━━━━━━┻┳━━━━━━━━┻┳━━━━━━━━┻┳━━━━━━━━┻┳━━━━━━━━┻┳━━━━━━━━┻┳━━━━━━━━┻┳━━━━━━━━┻┳━━━━━━━━┻━━━━━━━━━┫
    ┃           ┃         ┃         ┃         ┃         ┃         ┃         ┃         ┃         ┃         ┃         ┃         ┃                  ┃
    ┃           ┃         ┃         ┃         ┃         ┃         ┃         ┃  ( )+←  ┃  { }+←  ┃  [ ]+←  ┃         ┃         ┃                  ┃
    ┃           ┃         ┃         ┃         ┃         ┃         ┃         ┃         ┃         ┃         ┃         ┃         ┃                  ┃
    ┣━━━━━━━━━━━┻━━┳━━━━━━┻━━┳━━━━━━┻━━┳━━━━━━┻━━┳━━━━━━┻━━┳━━━━━━┻━━┳━━━━━━┻━━┳━━━━━━┻━━┳━━━━━━┻━━┳━━━━━━┻━━┳━━━━━━┻━━┳━━━━━━┻━━━━━━━━━━━━━━━━━━┫
    ┃              ┃         ┃         ┃         ┃         ┃         ┃         ┃         ┃         ┃         ┃         ┃                         ┃
    ┃              ┃         ┃         ┃         ┃         ┃         ┃         ┃  < >+←  ┃         ┃         ┃         ┃                         ┃
    ┃              ┃         ┃         ┃         ┃         ┃         ┃         ┃         ┃         ┃         ┃         ┃                         ┃
    ┣━━━━━━━━━━━┳━━┻━━━━━━━┳━┻━━━━━━━━━╋━━━━━━━━━┻━━━━━━━━━┻━━━━━━━━━┻━━━━━━━━━┻━━━━━━━━━╋━━━━━━━━━┻━━━━┳━━━━┻━━━━━┳━┳━┻━━━━━━┳━━━━━━━━━┳━━━━━━━━┫
    ┃           ┃          ┃           ┃                                                 ┃              ┃          ┃ ┃        ┃         ┃        ┃
    ┃           ┃          ┃           ┃                                                 ┃              ┃          ┃ ┃        ┣━━━━━━━━━┫        ┃
    ┃           ┃          ┃           ┃                                                 ┃              ┃          ┃ ┃        ┃         ┃        ┃
    ┗━━━━━━━━━━━┻━━━━━━━━━━┻━━━━━━━━━━━┻━━━━━━━━━━━━━━━━━━━━━━━━━━━━━━━━━━━━━━━━━━━━━━━━━┻━━━━━━━━━━━━━━┻━━━━━━━━━━┛ ┗━━━━━━━━┻━━━━━━━━━┻━━━━━━━━┛
    */
    layer_w_mcro {
      bindings = <
        //ESC           //f1            //f2            //f3            //f4           //f5   //f6   //f7           //f8          //f9            //f10  //f11  //f12  //DEL
        &to LYR_W_BASE  &none           &none           &none           &none          &none  &none  &none          &none         &none           &none  &none  &none  &none
        &none           &to LYR_W_FUNC  &to LYR_W_SYM1  &to LYR_W_NAV1  &to LYR_W_UAT  &none  &none  &none          &none         &none           &none  &none  &none  &none
        &none           &none           &none           &none           &none          &none  &none  &none          &none         &none           &none  &none  &none  &none
        &none           &none           &none           &none           &none          &none  &none  &mcro_parens   &mcro_braces  &mcro_brackets  &none  &none  &none
        &none           &none           &none           &none           &none          &none  &none  &mcro_angle_brackets &none    &none           &none  &none
        &none           &none           &none           &none           &none          &none  &none  &none          &none         &none
        &none           &none           &none           &none           &none
      >;
    };
  };
};
